VERSION ""

NS_ :

BS_:

BU_: ACC ASWS GVCU HUB_DYNO IEB IMU LOGGER

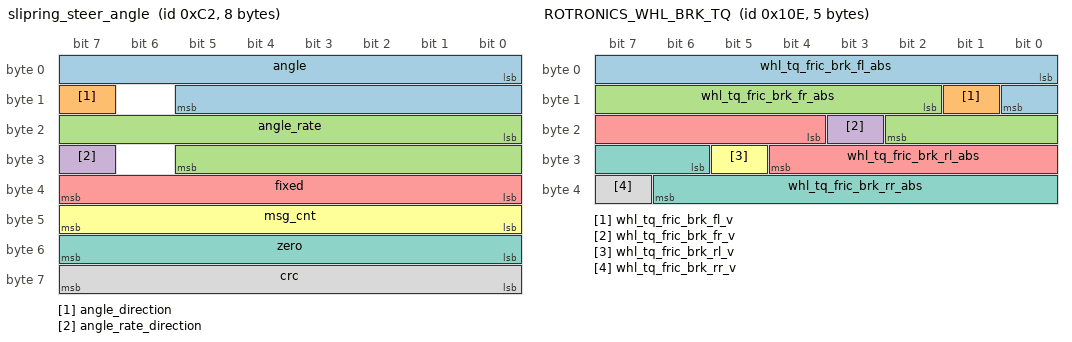
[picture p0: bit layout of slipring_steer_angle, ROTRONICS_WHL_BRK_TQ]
BO_ 194 slipring_steer_angle: 8 ASWS
 SG_ angle : 0|14@1+ (0.04372,0) [0|716] "deg"  GVCU
 SG_ angle_direction : 15|1@1+ (1,0) [0|1] "enum"  GVCU
 SG_ angle_rate : 16|14@1+ (0.04372,0) [0|716] "deg/s"  GVCU
 SG_ angle_rate_direction : 31|1@1+ (1,0) [0|1] "enum"  GVCU
 SG_ fixed : 32|8@1+ (1,0) [0|255] ""  GVCU
 SG_ msg_cnt : 40|8@1+ (1,0) [0|255] ""  GVCU
 SG_ zero : 48|8@1+ (1,0) [0|255] ""  GVCU
 SG_ crc : 56|8@1+ (1,0) [0|255] ""  GVCU

BO_ 260 ROTRONICS_SPD: 8 HUB_DYNO
 SG_ SpeedDyno1_RPM : 0|16@1+ (0.1,-2000) [-2000|4000] "rpm"  GVCU
 SG_ SpeedDyno2_RPM : 16|16@1+ (0.1,-2000) [-2000|4000] "rpm"  GVCU
 SG_ SpeedDyno3_RPM : 32|16@1+ (0.1,-2000) [-2000|4000] "rpm"  GVCU
 SG_ SpeedDyno4_RPM : 48|16@1+ (0.1,-2000) [-2000|4000] "rpm"  GVCU

BO_ 269 ROTRONICS_LIN_ACCEL: 2 HUB_DYNO
 SG_ VehicleAccelN : 0|16@1+ (0.002,-65.532) [-65.532|65.532] "m/s2"  GVCU

BO_ 270 ROTRONICS_WHL_BRK_TQ: 5 GVCU
 SG_ whl_tq_fric_brk_fl_abs : 0|9@1+ (10,0) [0|5000] "Nm"  HUB_DYNO
 SG_ whl_tq_fric_brk_fl_v : 9|1@1+ (1,0) [0|1] "bool"  HUB_DYNO
 SG_ whl_tq_fric_brk_fr_abs : 10|9@1+ (10,0) [0|5000] "Nm"  HUB_DYNO
 SG_ whl_tq_fric_brk_fr_v : 19|1@1+ (1,0) [0|1] "bool"  HUB_DYNO
 SG_ whl_tq_fric_brk_rl_abs : 20|9@1+ (10,0) [0|5000] "Nm"  HUB_DYNO
 SG_ whl_tq_fric_brk_rl_v : 29|1@1+ (1,0) [0|1] "bool"  HUB_DYNO
 SG_ whl_tq_fric_brk_rr_abs : 30|9@1+ (10,0) [0|5000] "Nm"  HUB_DYNO
 SG_ whl_tq_fric_brk_rr_v : 39|1@1+ (1,0) [0|1] "bool"  HUB_DYNO

BO_ 450 vehicle_speed_raw: 4 IEB
 SG_ e2e_checksum : 0|8@1+ (1,0) [0|255] ""  LOGGER
 SG_ e2e_alive_counter : 8|4@1+ (1,0) [0|15] "enum"  LOGGER
 SG_ vehicle_speed_r_v : 12|1@1+ (1,0) [0|1] "enum"  LOGGER
 SG_ vehicle_speed_r : 16|16@1+ (0.01,0) [0|655] "km/h"  LOGGER

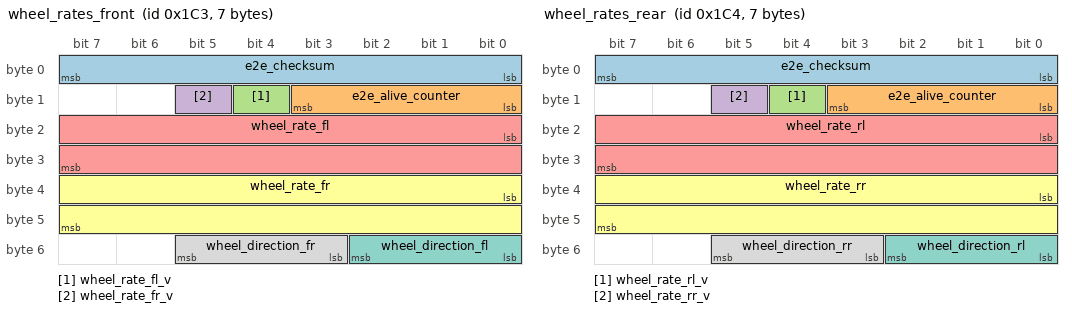
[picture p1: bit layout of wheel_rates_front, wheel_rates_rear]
BO_ 451 wheel_rates_front: 7 IEB
 SG_ e2e_checksum : 0|8@1+ (1,0) [0|255] ""  GVCU
 SG_ e2e_alive_counter : 8|4@1+ (1,0) [0|15] "enum"  GVCU
 SG_ wheel_rate_fl_v : 12|1@1+ (1,0) [0|1] "enum"  GVCU
 SG_ wheel_rate_fr_v : 13|1@1+ (1,0) [0|1] "enum"  GVCU
 SG_ wheel_rate_fl : 16|16@1+ (0.01,0) [0|655.35] "rad/s"  GVCU
 SG_ wheel_rate_fr : 32|16@1+ (0.01,0) [0|655.35] "rad/s"  GVCU
 SG_ wheel_direction_fl : 48|3@1+ (1,0) [0|5] "enum"  GVCU
 SG_ wheel_direction_fr : 51|3@1+ (1,0) [0|5] "enum"  GVCU

BO_ 452 wheel_rates_rear: 7 IEB
 SG_ e2e_checksum : 0|8@1+ (1,0) [0|255] ""  GVCU
 SG_ e2e_alive_counter : 8|4@1+ (1,0) [0|15] "enum"  GVCU
 SG_ wheel_rate_rl_v : 12|1@1+ (1,0) [0|1] "enum"  GVCU
 SG_ wheel_rate_rr_v : 13|1@1+ (1,0) [0|1] "enum"  GVCU
 SG_ wheel_rate_rl : 16|16@1+ (0.01,0) [0|655.35] "rad/s"  GVCU
 SG_ wheel_rate_rr : 32|16@1+ (0.01,0) [0|655.35] "rad/s"  GVCU
 SG_ wheel_direction_rl : 48|3@1+ (1,0) [0|5] "enum"  GVCU
 SG_ wheel_direction_rr : 51|3@1+ (1,0) [0|5] "enum"  GVCU

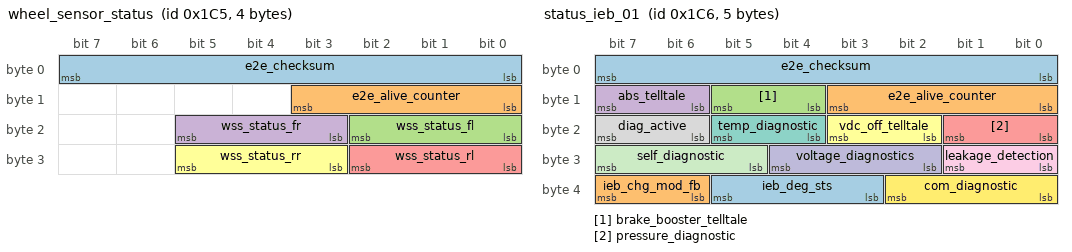
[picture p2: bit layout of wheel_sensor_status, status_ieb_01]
BO_ 453 wheel_sensor_status: 4 IEB
 SG_ e2e_checksum : 0|8@1+ (1,0) [0|255] ""  GVCU
 SG_ e2e_alive_counter : 8|4@1+ (1,0) [0|15] "enum"  GVCU
 SG_ wss_status_fl : 16|3@1+ (1,0) [0|6] "enum"  GVCU
 SG_ wss_status_fr : 19|3@1+ (1,0) [0|6] "enum"  GVCU
 SG_ wss_status_rl : 24|3@1+ (1,0) [0|6] "enum"  GVCU
 SG_ wss_status_rr : 27|3@1+ (1,0) [0|6] "enum"  GVCU

BO_ 454 status_ieb_01: 5 IEB
 SG_ e2e_checksum : 0|8@1+ (1,0) [0|255] ""  GVCU
 SG_ e2e_alive_counter : 8|4@1+ (1,0) [0|15] "enum"  GVCU
 SG_ brake_booster_telltale : 12|2@1+ (1,0) [0|2] "enum"  GVCU
 SG_ abs_telltale : 14|2@1+ (1,0) [0|2] "enum"  GVCU
 SG_ pressure_diagnostic : 16|2@1+ (1,0) [0|3] "enum"  GVCU
 SG_ vdc_off_telltale : 18|2@1+ (1,0) [0|2] "enum"  GVCU
 SG_ temp_diagnostic : 20|2@1+ (1,0) [0|3] "enum"  GVCU
 SG_ diag_active : 22|2@1+ (1,0) [0|2] "enum"  GVCU
 SG_ leakage_detection : 24|2@1+ (1,0) [0|3] "enum"  GVCU
 SG_ voltage_diagnostics : 26|3@1+ (1,0) [0|4] "enum"  GVCU
 SG_ self_diagnostic : 29|3@1+ (1,0) [0|3] "enum"  GVCU
 SG_ com_diagnostic : 32|3@1+ (1,0) [0|3] "enum"  GVCU
 SG_ ieb_deg_sts : 35|3@1+ (1,0) [0|4] "enum"  GVCU
 SG_ ieb_chg_mod_fb : 38|2@1+ (1,0) [0|2] "enum"  GVCU

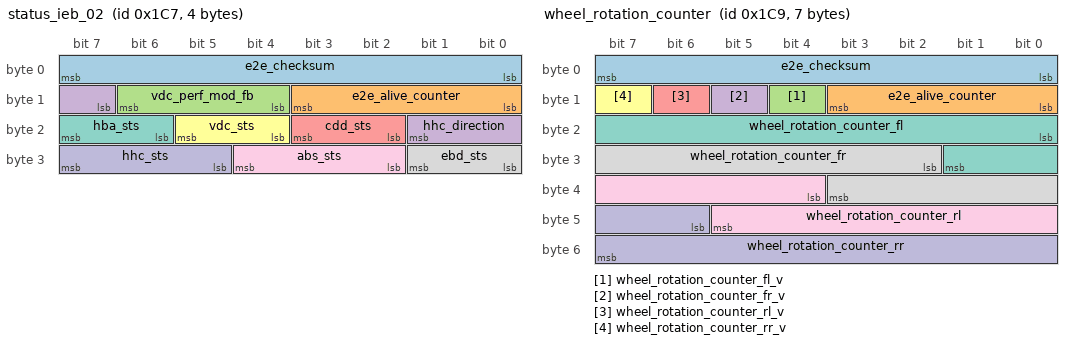
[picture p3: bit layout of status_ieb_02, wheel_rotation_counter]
BO_ 455 status_ieb_02: 4 IEB
 SG_ e2e_checksum : 0|8@1+ (1,0) [0|255] ""  GVCU
 SG_ e2e_alive_counter : 8|4@1+ (1,0) [0|15] "enum"  GVCU
 SG_ vdc_perf_mod_fb : 12|3@1+ (1,0) [0|4] "enum"  GVCU
 SG_ hhc_direction : 15|3@1+ (1,0) [0|3] "enum"  LOGGER
 SG_ cdd_sts : 18|2@1+ (1,0) [0|3] "enum"  GVCU
 SG_ vdc_sts : 20|2@1+ (1,0) [0|3] "enum"  GVCU
 SG_ hba_sts : 22|2@1+ (1,0) [0|3] "enum"  GVCU
 SG_ ebd_sts : 24|2@1+ (1,0) [0|3] "enum"  GVCU
 SG_ abs_sts : 26|3@1+ (1,0) [0|4] "enum"  GVCU
 SG_ hhc_sts : 29|3@1+ (1,0) [0|4] "enum"  GVCU

BO_ 457 wheel_rotation_counter: 7 IEB
 SG_ e2e_checksum : 0|8@1+ (1,0) [0|255] ""  GVCU
 SG_ e2e_alive_counter : 8|4@1+ (1,0) [0|15] "enum"  GVCU
 SG_ wheel_rotation_counter_fl_v : 12|1@1+ (1,0) [0|1] "enum"  GVCU
 SG_ wheel_rotation_counter_fr_v : 13|1@1+ (1,0) [0|1] "enum"  GVCU
 SG_ wheel_rotation_counter_rl_v : 14|1@1+ (1,0) [0|1] "enum"  GVCU
 SG_ wheel_rotation_counter_rr_v : 15|1@1+ (1,0) [0|1] "enum"  GVCU
 SG_ wheel_rotation_counter_fl : 16|10@1+ (1,0) [0|1023] "enum"  GVCU
 SG_ wheel_rotation_counter_fr : 26|10@1+ (1,0) [0|1023] "enum"  GVCU
 SG_ wheel_rotation_counter_rl : 36|10@1+ (1,0) [0|1023] "enum"  GVCU
 SG_ wheel_rotation_counter_rr : 46|10@1+ (1,0) [0|1023] "enum"  GVCU

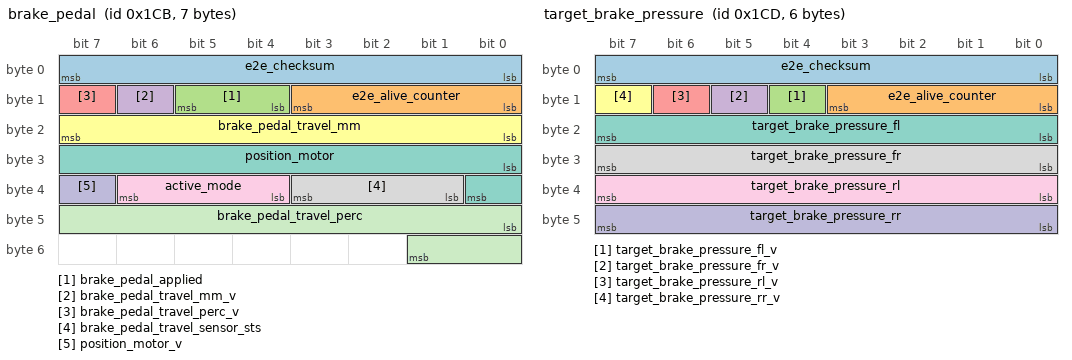
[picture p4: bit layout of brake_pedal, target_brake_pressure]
BO_ 459 brake_pedal: 7 IEB
 SG_ e2e_checksum : 0|8@1+ (1,0) [0|255] ""  GVCU
 SG_ e2e_alive_counter : 8|4@1+ (1,0) [0|15] "enum"  GVCU
 SG_ brake_pedal_applied : 12|2@1+ (1,0) [0|3] "enum"  GVCU
 SG_ brake_pedal_travel_mm_v : 14|1@1+ (1,0) [0|1] "enum"  GVCU
 SG_ brake_pedal_travel_perc_v : 15|1@1+ (1,0) [0|1] "enum"  GVCU
 SG_ brake_pedal_travel_mm : 16|8@1+ (0.1,0) [0|25.5] "mm"  GVCU
 SG_ position_motor : 24|9@1+ (0.1,-2) [-2|49.1] "mm"  GVCU
 SG_ brake_pedal_travel_sensor_sts : 33|3@1+ (1,0) [0|4] "enum"  GVCU
 SG_ active_mode : 36|3@1+ (1,0) [0|5] "enum"  GVCU
 SG_ position_motor_v : 39|1@1+ (1,0) [0|1] "enum"  GVCU
 SG_ brake_pedal_travel_perc : 40|10@1+ (0.1,0) [0|100] "%"  GVCU

BO_ 461 target_brake_pressure: 6 IEB
 SG_ e2e_checksum : 0|8@1+ (1,0) [0|255] ""  GVCU
 SG_ e2e_alive_counter : 8|4@1+ (1,0) [0|15] "enum"  GVCU
 SG_ target_brake_pressure_fl_v : 12|1@1+ (1,0) [0|1] "enum"  GVCU
 SG_ target_brake_pressure_fr_v : 13|1@1+ (1,0) [0|1] "enum"  GVCU
 SG_ target_brake_pressure_rl_v : 14|1@1+ (1,0) [0|1] "enum"  GVCU
 SG_ target_brake_pressure_rr_v : 15|1@1+ (1,0) [0|1] "enum"  GVCU
 SG_ target_brake_pressure_fl : 16|8@1+ (1,0) [0|255] "bar"  GVCU
 SG_ target_brake_pressure_fr : 24|8@1+ (1,0) [0|255] "bar"  GVCU
 SG_ target_brake_pressure_rl : 32|8@1+ (1,0) [0|255] "bar"  GVCU
 SG_ target_brake_pressure_rr : 40|8@1+ (1,0) [0|255] "bar"  GVCU

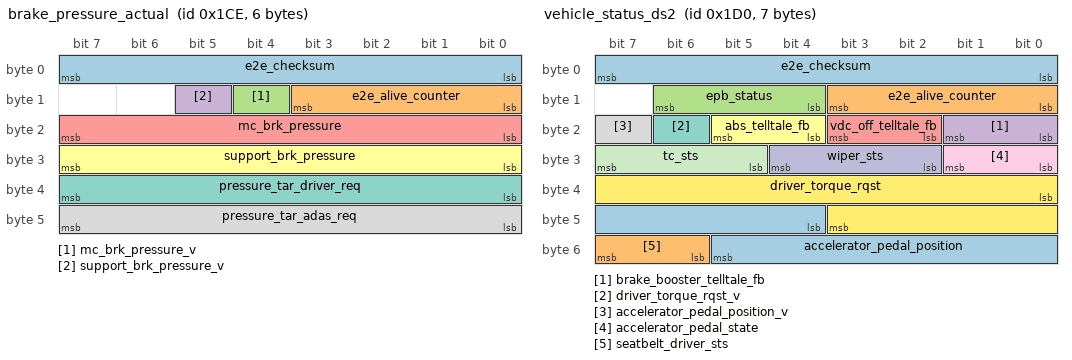
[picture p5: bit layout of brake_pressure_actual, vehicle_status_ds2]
BO_ 462 brake_pressure_actual: 6 IEB
 SG_ e2e_checksum : 0|8@1+ (1,0) [0|255] ""  GVCU
 SG_ e2e_alive_counter : 8|4@1+ (1,0) [0|15] "enum"  GVCU
 SG_ mc_brk_pressure_v : 12|1@1+ (1,0) [0|1] "enum"  GVCU
 SG_ support_brk_pressure_v : 13|1@1+ (1,0) [0|1] "enum"  GVCU
 SG_ mc_brk_pressure : 16|8@1+ (1,0) [0|255] "bar"  GVCU
 SG_ support_brk_pressure : 24|8@1+ (1,0) [0|255] "bar"  GVCU
 SG_ pressure_tar_driver_req : 32|8@1+ (1,0) [0|255] "bar"  GVCU
 SG_ pressure_tar_adas_req : 40|8@1+ (1,0) [0|255] "bar"  LOGGER

BO_ 464 vehicle_status_ds2: 7 GVCU
 SG_ e2e_checksum : 0|8@1+ (1,0) [0|255] ""  IEB
 SG_ e2e_alive_counter : 8|4@1+ (1,0) [0|15] "enum"  IEB
 SG_ epb_status : 12|3@1+ (1,0) [0|5] "enum"  IEB
 SG_ brake_booster_telltale_fb : 16|2@1+ (1,0) [0|2] "enum"  IEB
 SG_ vdc_off_telltale_fb : 18|2@1+ (1,0) [0|2] "enum"  IEB
 SG_ abs_telltale_fb : 20|2@1+ (1,0) [0|2] "enum"  IEB
 SG_ driver_torque_rqst_v : 22|1@1+ (1,0) [0|1] "enum"  IEB
 SG_ accelerator_pedal_position_v : 23|1@1+ (1,0) [0|1] "enum"  IEB
 SG_ accelerator_pedal_state : 24|2@1+ (1,0) [0|3] "enum"  IEB
 SG_ wiper_sts : 26|3@1+ (1,0) [0|4] "enum"  IEB
 SG_ tc_sts : 29|3@1+ (1,0) [0|4] "enum"  IEB
 SG_ driver_torque_rqst : 32|12@1+ (1,0) [0|4095] "Nm"  IEB
 SG_ accelerator_pedal_position : 44|10@1+ (0.1,0) [0|100] "%"  IEB
 SG_ seatbelt_driver_sts : 54|2@1+ (1,0) [0|2] "enum"  IEB

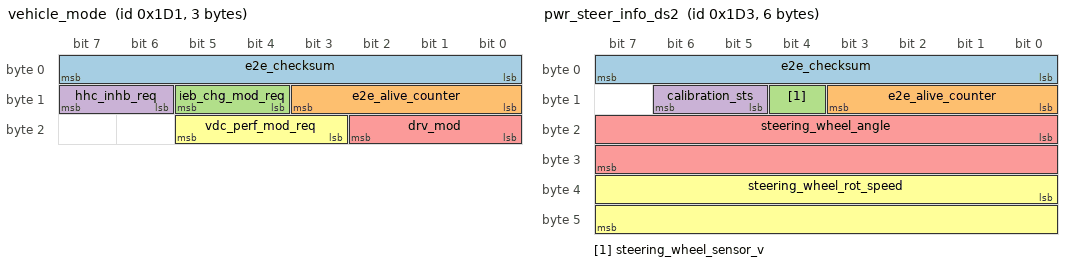
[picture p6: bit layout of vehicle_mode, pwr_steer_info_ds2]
BO_ 465 vehicle_mode: 3 GVCU
 SG_ e2e_checksum : 0|8@1+ (1,0) [0|255] ""  IEB
 SG_ e2e_alive_counter : 8|4@1+ (1,0) [0|15] "enum"  IEB
 SG_ ieb_chg_mod_req : 12|2@1+ (1,0) [0|2] "enum"  IEB
 SG_ hhc_inhb_req : 14|2@1+ (1,0) [0|2] "enum"  IEB
 SG_ drv_mod : 16|3@1+ (1,0) [0|4] "enum"  IEB
 SG_ vdc_perf_mod_req : 19|3@1+ (1,0) [0|3] "enum"  IEB

BO_ 467 pwr_steer_info_ds2: 6 GVCU
 SG_ e2e_checksum : 0|8@1+ (1,0) [0|255] ""  ACC,IEB
 SG_ e2e_alive_counter : 8|4@1+ (1,0) [0|15] "enum"  ACC,IEB
 SG_ steering_wheel_sensor_v : 12|1@1+ (1,0) [0|1] "enum"  ACC,IEB
 SG_ calibration_sts : 13|2@1+ (1,0) [0|2] "enum"  ACC,IEB
 SG_ steering_wheel_angle : 16|16@1+ (0.1,-780) [-780|780] "deg"  ACC,IEB
 SG_ steering_wheel_rot_speed : 32|16@1+ (0.1,-1016) [-1016|1016] "deg/s"  ACC,IEB

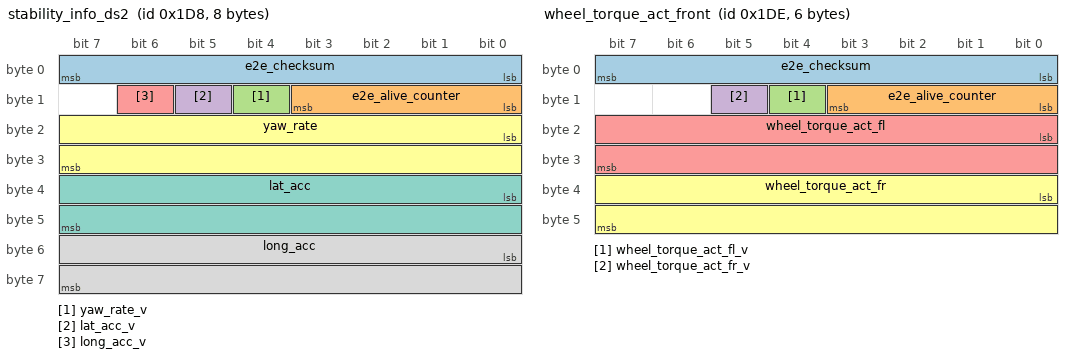
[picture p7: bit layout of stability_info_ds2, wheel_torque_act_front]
BO_ 472 stability_info_ds2: 8 GVCU
 SG_ e2e_checksum : 0|8@1+ (1,0) [0|255] ""  ACC,IEB
 SG_ e2e_alive_counter : 8|4@1+ (1,0) [0|15] "enum"  ACC,IEB
 SG_ yaw_rate_v : 12|1@1+ (1,0) [0|1] "enum"  ACC,IEB
 SG_ lat_acc_v : 13|1@1+ (1,0) [0|1] "enum"  ACC,IEB
 SG_ long_acc_v : 14|1@1+ (1,0) [0|1] "enum"  ACC,IEB
 SG_ yaw_rate : 16|16@1+ (0.005,-163.83) [-163.83|163.845] "deg/s"  ACC,IEB
 SG_ lat_acc : 32|16@1+ (0.002,-65.532) [-65.532|65.538] "m/s2"  ACC,IEB
 SG_ long_acc : 48|16@1+ (0.002,-65.532) [-65.532|65.532] "m/s2"  ACC,IEB

BO_ 475 driver_assistance_01: 2 GVCU
 SG_ e2e_checksum : 0|8@1+ (1,0) [0|255] ""  IEB
 SG_ e2e_alive_counter : 8|4@1+ (1,0) [0|15] "enum"  IEB
 SG_ brake_jerk_req : 12|2@1+ (1,0) [0|2] "enum"  IEB
 SG_ prefill_req : 14|2@1+ (1,0) [0|2] "enum"  IEB

BO_ 478 wheel_torque_act_front: 6 GVCU
 SG_ e2e_checksum : 0|8@1+ (1,0) [0|255] ""  IEB
 SG_ e2e_alive_counter : 8|4@1+ (1,0) [0|15] "enum"  IEB
 SG_ wheel_torque_act_fl_v : 12|1@1+ (1,0) [0|1] "enum"  IEB
 SG_ wheel_torque_act_fr_v : 13|1@1+ (1,0) [0|1] "enum"  IEB
 SG_ wheel_torque_act_fl : 16|16@1+ (1,-32767) [-32767|32767] "Nm"  IEB
 SG_ wheel_torque_act_fr : 32|16@1+ (1,-32767) [-32767|32767] "Nm"  IEB

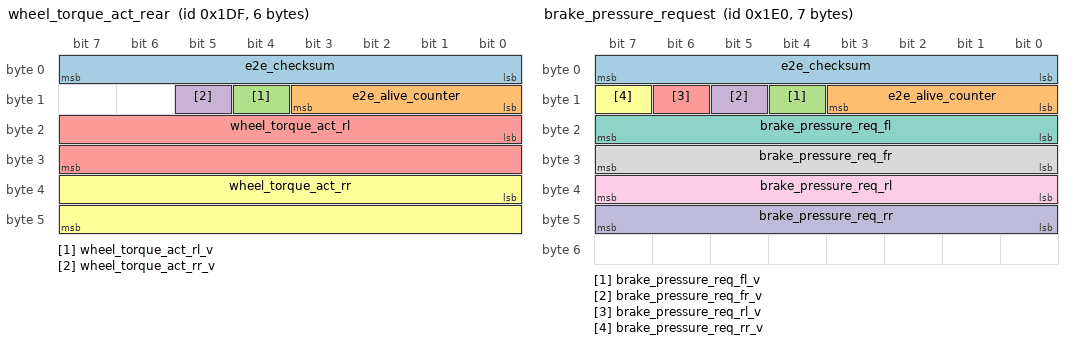
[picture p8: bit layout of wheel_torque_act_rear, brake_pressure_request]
BO_ 479 wheel_torque_act_rear: 6 GVCU
 SG_ e2e_checksum : 0|8@1+ (1,0) [0|255] ""  IEB
 SG_ e2e_alive_counter : 8|4@1+ (1,0) [0|15] "enum"  IEB
 SG_ wheel_torque_act_rl_v : 12|1@1+ (1,0) [0|1] "enum"  IEB
 SG_ wheel_torque_act_rr_v : 13|1@1+ (1,0) [0|1] "enum"  IEB
 SG_ wheel_torque_act_rl : 16|16@1+ (1,-32767) [-32767|32767] "Nm"  IEB
 SG_ wheel_torque_act_rr : 32|16@1+ (1,-32767) [-32767|32767] "Nm"  IEB

BO_ 480 brake_pressure_request: 7 GVCU
 SG_ e2e_checksum : 0|8@1+ (1,0) [0|255] ""  IEB
 SG_ e2e_alive_counter : 8|4@1+ (1,0) [0|15] "enum"  IEB
 SG_ brake_pressure_req_fl_v : 12|1@1+ (1,0) [0|1] "enum"  IEB
 SG_ brake_pressure_req_fr_v : 13|1@1+ (1,0) [0|1] "enum"  IEB
 SG_ brake_pressure_req_rl_v : 14|1@1+ (1,0) [0|1] "enum"  IEB
 SG_ brake_pressure_req_rr_v : 15|1@1+ (1,0) [0|1] "enum"  IEB
 SG_ brake_pressure_req_fl : 16|8@1+ (1,0) [0|200] "bar"  IEB
 SG_ brake_pressure_req_fr : 24|8@1+ (1,0) [0|200] "bar"  IEB
 SG_ brake_pressure_req_rl : 32|8@1+ (1,0) [0|200] "bar"  IEB
 SG_ brake_pressure_req_rr : 40|8@1+ (1,0) [0|200] "bar"  IEB

BO_ 483 regen_01: 4 IEB
 SG_ e2e_checksum : 0|8@1+ (1,0) [0|255] ""  GVCU
 SG_ e2e_alive_counter : 8|4@1+ (1,0) [0|15] "enum"  GVCU
 SG_ reg_sts : 12|2@1+ (1,0) [0|2] "enum"  GVCU
 SG_ recu_brake_torque_req_v : 14|1@1+ (1,0) [0|1] "enum"  GVCU
 SG_ recu_brake_torque_req : 16|16@1+ (1,-32767) [-32767|0] "Nm"  GVCU

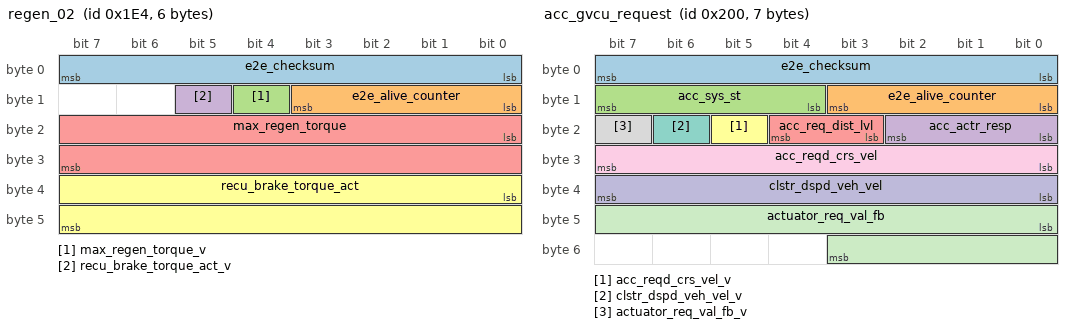
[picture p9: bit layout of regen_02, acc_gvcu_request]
BO_ 484 regen_02: 6 GVCU
 SG_ e2e_checksum : 0|8@1+ (1,0) [0|255] ""  IEB
 SG_ e2e_alive_counter : 8|4@1+ (1,0) [0|15] "enum"  IEB
 SG_ max_regen_torque_v : 12|1@1+ (1,0) [0|1] "enum"  IEB
 SG_ recu_brake_torque_act_v : 13|1@1+ (1,0) [0|1] "enum"  IEB
 SG_ max_regen_torque : 16|16@1+ (1,-32767) [-32767|0] "Nm"  IEB
 SG_ recu_brake_torque_act : 32|16@1+ (1,-32767) [-32767|0] "Nm"  IEB

BO_ 512 acc_gvcu_request: 7 GVCU
 SG_ e2e_checksum : 0|8@1+ (1,0) [0|255] ""  ACC
 SG_ e2e_alive_counter : 8|4@1+ (1,0) [0|15] "enum"  ACC
 SG_ acc_sys_st : 12|4@1+ (1,0) [0|8] "enum"  ACC
 SG_ acc_actr_resp : 16|3@1+ (1,0) [0|5] "enum"  ACC
 SG_ acc_req_dist_lvl : 19|2@1+ (1,0) [0|3] "enum"  ACC
 SG_ acc_reqd_crs_vel_v : 21|1@1+ (1,0) [0|1] "enum"  ACC
 SG_ clstr_dspd_veh_vel_v : 22|1@1+ (1,0) [0|1] "enum"  ACC
 SG_ actuator_req_val_fb_v : 23|1@1+ (1,0) [0|1] "enum"  ACC
 SG_ acc_reqd_crs_vel : 24|8@1+ (1,0) [0|255] "km/h"  ACC
 SG_ clstr_dspd_veh_vel : 32|8@1+ (1,0) [0|255] "km/h"  ACC
 SG_ actuator_req_val_fb : 40|12@1+ (0.002,-5) [-5|3.19] "m/s2"  ACC

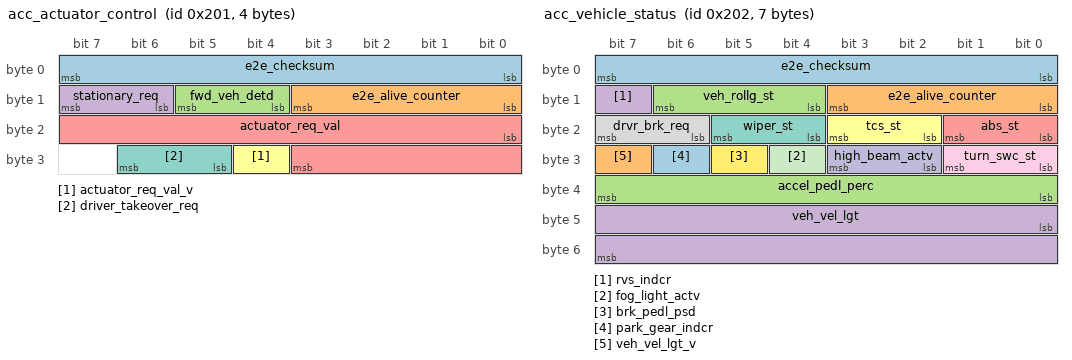
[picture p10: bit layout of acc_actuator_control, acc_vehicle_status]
BO_ 513 acc_actuator_control: 4 ACC
 SG_ e2e_checksum : 0|8@1+ (1,0) [0|255] ""  GVCU
 SG_ e2e_alive_counter : 8|4@1+ (1,0) [0|15] "enum"  GVCU
 SG_ fwd_veh_detd : 12|2@1+ (1,0) [0|2] "enum"  GVCU
 SG_ stationary_req : 14|2@1+ (1,0) [0|2] "enum"  GVCU
 SG_ actuator_req_val : 16|12@1+ (0.002,-5) [-5|3.19] "m/s2"  GVCU
 SG_ actuator_req_val_v : 28|1@1+ (1,0) [0|1] "enum"  GVCU
 SG_ driver_takeover_req : 29|2@1+ (1,0) [0|2] "enum"  GVCU

BO_ 514 acc_vehicle_status: 7 GVCU
 SG_ e2e_checksum : 0|8@1+ (1,0) [0|255] ""  ACC
 SG_ e2e_alive_counter : 8|4@1+ (1,0) [0|15] "enum"  ACC
 SG_ veh_rollg_st : 12|3@1+ (1,0) [0|4] "enum"  ACC
 SG_ rvs_indcr : 15|1@1+ (1,0) [0|1] "bool"  ACC
 SG_ abs_st : 16|2@1+ (1,0) [0|3] "enum"  ACC
 SG_ tcs_st : 18|2@1+ (1,0) [0|3] "enum"  ACC
 SG_ wiper_st : 20|2@1+ (1,0) [0|3] "enum"  ACC
 SG_ drvr_brk_req : 22|2@1+ (1,0) [0|2] "enum"  ACC
 SG_ turn_swc_st : 24|2@1+ (1,0) [0|2] "enum"  ACC
 SG_ high_beam_actv : 26|2@1+ (1,0) [0|2] "enum"  ACC
 SG_ fog_light_actv : 28|1@1+ (1,0) [0|1] "bool"  ACC
 SG_ brk_pedl_psd : 29|1@1+ (1,0) [0|1] "bool"  ACC
 SG_ park_gear_indcr : 30|1@1+ (1,0) [0|1] "bool"  ACC
 SG_ veh_vel_lgt_v : 31|1@1+ (1,0) [0|1] "enum"  ACC
 SG_ accel_pedl_perc : 32|8@1+ (0.392157,0) [0|100] "%"  ACC
 SG_ veh_vel_lgt : 40|16@1+ (0.002,0) [0|131.064] "m/s"  ACC

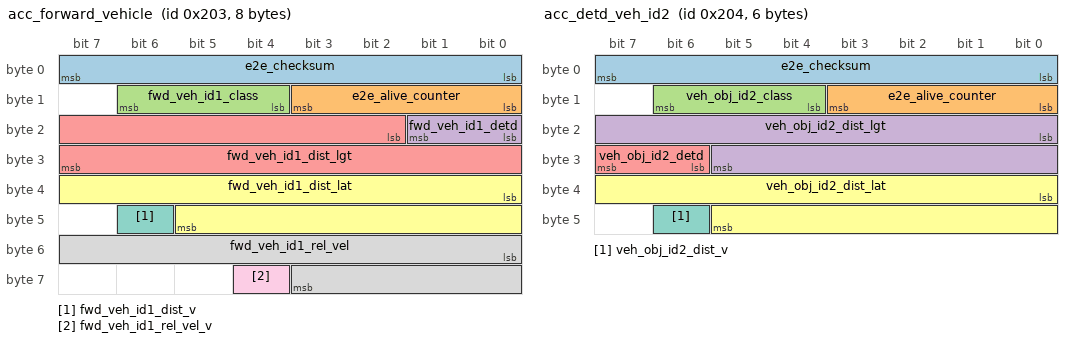
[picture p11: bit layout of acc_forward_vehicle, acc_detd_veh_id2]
BO_ 515 acc_forward_vehicle: 8 ACC
 SG_ e2e_checksum : 0|8@1+ (1,0) [0|255] ""  GVCU
 SG_ e2e_alive_counter : 8|4@1+ (1,0) [0|15] "enum"  GVCU
 SG_ fwd_veh_id1_class : 12|3@1+ (1,0) [0|4] "enum"  LOGGER
 SG_ fwd_veh_id1_detd : 16|2@1+ (1,0) [0|2] "enum"  GVCU
 SG_ fwd_veh_id1_dist_lgt : 18|14@1+ (0.02,0) [0|327.66] "m"  GVCU
 SG_ fwd_veh_id1_dist_lat : 32|14@1+ (0.02,-163.84) [-163.84|163.82] "m"  GVCU
 SG_ fwd_veh_id1_dist_v : 46|1@1+ (1,0) [0|1] "enum"  GVCU
 SG_ fwd_veh_id1_rel_vel : 48|12@1+ (0.02,-41.6) [-41.6|40.3] "m/s"  GVCU
 SG_ fwd_veh_id1_rel_vel_v : 60|1@1+ (1,0) [0|1] "enum"  GVCU

BO_ 516 acc_detd_veh_id2: 6 ACC
 SG_ e2e_checksum : 0|8@1+ (1,0) [0|255] ""  GVCU
 SG_ e2e_alive_counter : 8|4@1+ (1,0) [0|15] "enum"  GVCU
 SG_ veh_obj_id2_class : 12|3@1+ (1,0) [0|4] "enum"  GVCU
 SG_ veh_obj_id2_dist_lgt : 16|14@1+ (0.02,0) [0|327.66] "m"  GVCU
 SG_ veh_obj_id2_detd : 30|2@1+ (1,0) [0|2] "enum"  GVCU
 SG_ veh_obj_id2_dist_lat : 32|14@1+ (0.02,-163.84) [-163.84|163.82] "m"  GVCU
 SG_ veh_obj_id2_dist_v : 46|1@1+ (1,0) [0|1] "enum"  GVCU

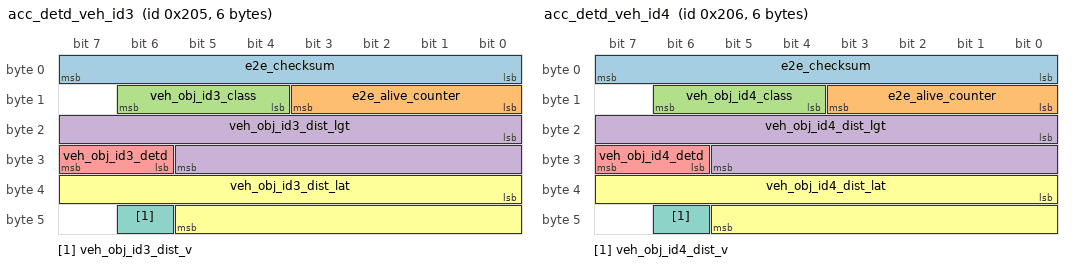
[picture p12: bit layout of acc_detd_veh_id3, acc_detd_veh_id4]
BO_ 517 acc_detd_veh_id3: 6 ACC
 SG_ e2e_checksum : 0|8@1+ (1,0) [0|255] ""  GVCU
 SG_ e2e_alive_counter : 8|4@1+ (1,0) [0|15] "enum"  GVCU
 SG_ veh_obj_id3_class : 12|3@1+ (1,0) [0|4] "enum"  GVCU
 SG_ veh_obj_id3_dist_lgt : 16|14@1+ (0.02,0) [0|327.66] "m"  GVCU
 SG_ veh_obj_id3_detd : 30|2@1+ (1,0) [0|2] "enum"  GVCU
 SG_ veh_obj_id3_dist_lat : 32|14@1+ (0.02,-163.84) [-163.84|163.82] "m"  GVCU
 SG_ veh_obj_id3_dist_v : 46|1@1+ (1,0) [0|1] "enum"  GVCU

BO_ 518 acc_detd_veh_id4: 6 ACC
 SG_ e2e_checksum : 0|8@1+ (1,0) [0|255] ""  GVCU
 SG_ e2e_alive_counter : 8|4@1+ (1,0) [0|15] "enum"  GVCU
 SG_ veh_obj_id4_class : 12|3@1+ (1,0) [0|4] "enum"  GVCU
 SG_ veh_obj_id4_dist_lgt : 16|14@1+ (0.02,0) [0|327.66] "m"  GVCU
 SG_ veh_obj_id4_detd : 30|2@1+ (1,0) [0|2] "enum"  GVCU
 SG_ veh_obj_id4_dist_lat : 32|14@1+ (0.02,-163.84) [-163.84|163.82] "m"  GVCU
 SG_ veh_obj_id4_dist_v : 46|1@1+ (1,0) [0|1] "enum"  GVCU

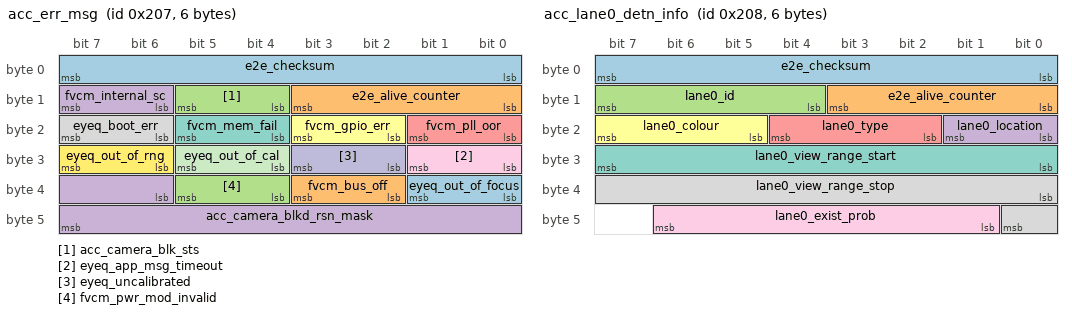
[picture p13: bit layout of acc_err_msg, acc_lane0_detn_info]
BO_ 519 acc_err_msg: 6 ACC
 SG_ e2e_checksum : 0|8@1+ (1,0) [0|255] ""  GVCU
 SG_ e2e_alive_counter : 8|4@1+ (1,0) [0|15] "enum"  GVCU
 SG_ acc_camera_blk_sts : 12|2@1+ (1,0) [0|2] "enum"  GVCU
 SG_ fvcm_internal_sc : 14|2@1+ (1,0) [0|2] "enum"  GVCU
 SG_ fvcm_pll_oor : 16|2@1+ (1,0) [0|2] "enum"  GVCU
 SG_ fvcm_gpio_err : 18|2@1+ (1,0) [0|2] "enum"  GVCU
 SG_ fvcm_mem_fail : 20|2@1+ (1,0) [0|2] "enum"  GVCU
 SG_ eyeq_boot_err : 22|2@1+ (1,0) [0|2] "enum"  GVCU
 SG_ eyeq_app_msg_timeout : 24|2@1+ (1,0) [0|2] "enum"  GVCU
 SG_ eyeq_uncalibrated : 26|2@1+ (1,0) [0|2] "enum"  GVCU
 SG_ eyeq_out_of_cal : 28|2@1+ (1,0) [0|2] "enum"  GVCU
 SG_ eyeq_out_of_rng : 30|2@1+ (1,0) [0|2] "enum"  GVCU
 SG_ eyeq_out_of_focus : 32|2@1+ (1,0) [0|2] "enum"  GVCU
 SG_ fvcm_bus_off : 34|2@1+ (1,0) [0|2] "enum"  GVCU
 SG_ fvcm_pwr_mod_invalid : 36|2@1+ (1,0) [0|2] "enum"  GVCU
 SG_ acc_camera_blkd_rsn_mask : 38|10@1+ (1,0) [0|1023] "enum"  GVCU

BO_ 520 acc_lane0_detn_info: 6 ACC
 SG_ e2e_checksum : 0|8@1+ (1,0) [0|255] ""  GVCU
 SG_ e2e_alive_counter : 8|4@1+ (1,0) [0|15] "enum"  GVCU
 SG_ lane0_id : 12|4@1+ (1,0) [0|15] "enum"  GVCU
 SG_ lane0_location : 16|2@1+ (1,0) [0|3] "enum"  GVCU
 SG_ lane0_type : 18|3@1+ (1,0) [0|6] "enum"  GVCU
 SG_ lane0_colour : 21|3@1+ (1,0) [0|4] "enum"  GVCU
 SG_ lane0_view_range_start : 24|8@1+ (0.25,0) [0|63.75] "m"  GVCU
 SG_ lane0_view_range_stop : 32|9@1+ (0.25,0) [0|127.75] "m"  GVCU
 SG_ lane0_exist_prob : 41|6@1+ (0.016,0) [0|1] "-"  GVCU

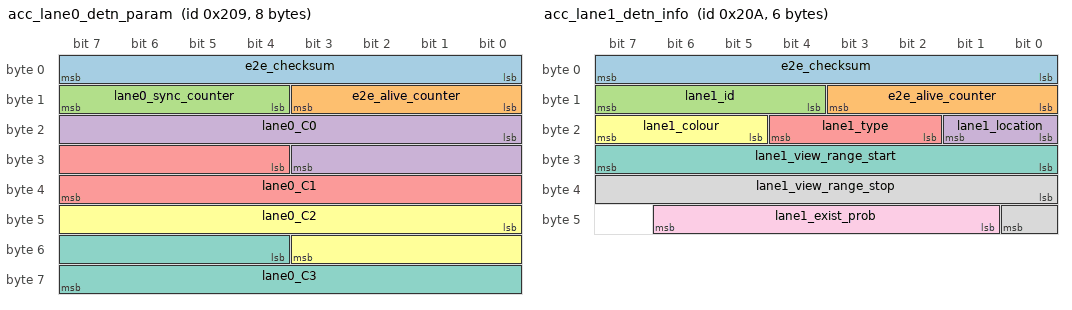
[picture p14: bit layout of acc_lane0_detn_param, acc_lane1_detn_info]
BO_ 521 acc_lane0_detn_param: 8 ACC
 SG_ e2e_checksum : 0|8@1+ (1,0) [0|255] ""  GVCU
 SG_ e2e_alive_counter : 8|4@1+ (1,0) [0|15] "enum"  GVCU
 SG_ lane0_sync_counter : 12|4@1+ (1,0) [0|15] ""  GVCU
 SG_ lane0_C0 : 16|12@1+ (0.004,-8) [-8|8] "m"  GVCU
 SG_ lane0_C1 : 28|12@1+ (0.0005,-1) [-1|1] "-"  GVCU
 SG_ lane0_C2 : 40|12@1+ (1.6e-05,-0.032) [-0.032|0.032] "m^-1"  GVCU
 SG_ lane0_C3 : 52|12@1+ (4.8e-07,-2.4e-07) [-2.4e-07|0.00196] "m^-2"  GVCU

BO_ 522 acc_lane1_detn_info: 6 ACC
 SG_ e2e_checksum : 0|8@1+ (1,0) [0|255] ""  GVCU
 SG_ e2e_alive_counter : 8|4@1+ (1,0) [0|15] "enum"  GVCU
 SG_ lane1_id : 12|4@1+ (1,0) [0|15] "enum"  GVCU
 SG_ lane1_location : 16|2@1+ (1,0) [0|3] "enum"  GVCU
 SG_ lane1_type : 18|3@1+ (1,0) [0|6] "enum"  GVCU
 SG_ lane1_colour : 21|3@1+ (1,0) [0|4] "enum"  GVCU
 SG_ lane1_view_range_start : 24|8@1+ (0.25,0) [0|63.75] "m"  GVCU
 SG_ lane1_view_range_stop : 32|9@1+ (0.25,0) [0|127.75] "m"  GVCU
 SG_ lane1_exist_prob : 41|6@1+ (0.016,0) [0|1] "-"  GVCU

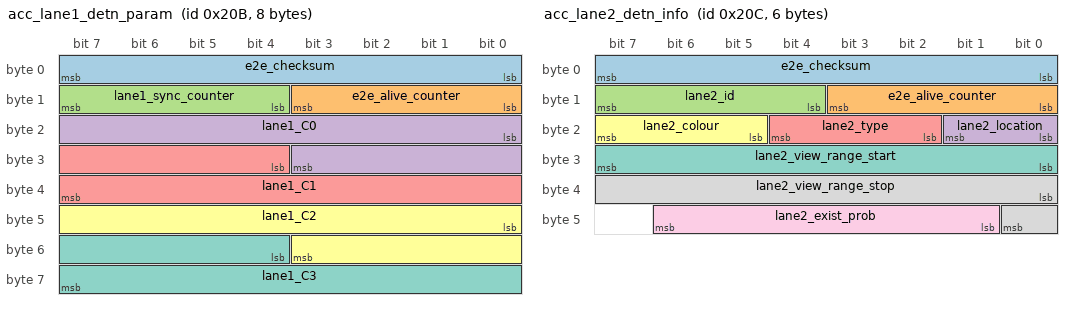
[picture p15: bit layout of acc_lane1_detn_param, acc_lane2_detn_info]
BO_ 523 acc_lane1_detn_param: 8 ACC
 SG_ e2e_checksum : 0|8@1+ (1,0) [0|255] ""  GVCU
 SG_ e2e_alive_counter : 8|4@1+ (1,0) [0|15] "enum"  GVCU
 SG_ lane1_sync_counter : 12|4@1+ (1,0) [0|15] ""  GVCU
 SG_ lane1_C0 : 16|12@1+ (0.004,-8) [-8|8] "m"  GVCU
 SG_ lane1_C1 : 28|12@1+ (0.0005,-1) [-1|1] "-"  GVCU
 SG_ lane1_C2 : 40|12@1+ (1.6e-05,-0.032) [-0.032|0.032] "m^-1"  GVCU
 SG_ lane1_C3 : 52|12@1+ (4.8e-07,-2.4e-07) [-2.4e-07|0.00196] "m^-2"  GVCU

BO_ 524 acc_lane2_detn_info: 6 ACC
 SG_ e2e_checksum : 0|8@1+ (1,0) [0|255] ""  GVCU
 SG_ e2e_alive_counter : 8|4@1+ (1,0) [0|15] "enum"  GVCU
 SG_ lane2_id : 12|4@1+ (1,0) [0|15] "enum"  GVCU
 SG_ lane2_location : 16|2@1+ (1,0) [0|3] "enum"  GVCU
 SG_ lane2_type : 18|3@1+ (1,0) [0|6] "enum"  GVCU
 SG_ lane2_colour : 21|3@1+ (1,0) [0|4] "enum"  GVCU
 SG_ lane2_view_range_start : 24|8@1+ (0.25,0) [0|63.75] "m"  GVCU
 SG_ lane2_view_range_stop : 32|9@1+ (0.25,0) [0|127.75] "m"  GVCU
 SG_ lane2_exist_prob : 41|6@1+ (0.016,0) [0|1] "-"  GVCU

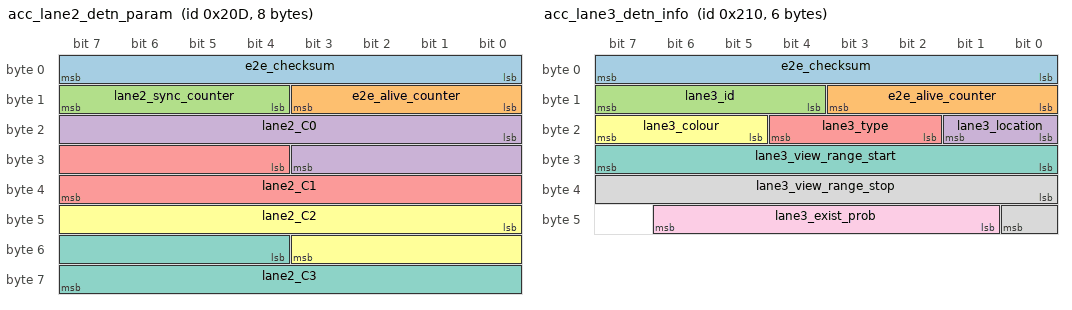
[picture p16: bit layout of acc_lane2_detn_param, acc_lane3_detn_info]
BO_ 525 acc_lane2_detn_param: 8 ACC
 SG_ e2e_checksum : 0|8@1+ (1,0) [0|255] ""  GVCU
 SG_ e2e_alive_counter : 8|4@1+ (1,0) [0|15] "enum"  GVCU
 SG_ lane2_sync_counter : 12|4@1+ (1,0) [0|15] ""  GVCU
 SG_ lane2_C0 : 16|12@1+ (0.004,-8) [-8|8] "m"  GVCU
 SG_ lane2_C1 : 28|12@1+ (0.0005,-1) [-1|1] "-"  GVCU
 SG_ lane2_C2 : 40|12@1+ (1.6e-05,-0.032) [-0.032|0.032] "m^-1"  GVCU
 SG_ lane2_C3 : 52|12@1+ (4.8e-07,-2.4e-07) [-2.4e-07|0.00196] "m^-2"  GVCU

BO_ 528 acc_lane3_detn_info: 6 ACC
 SG_ e2e_checksum : 0|8@1+ (1,0) [0|255] ""  GVCU
 SG_ e2e_alive_counter : 8|4@1+ (1,0) [0|15] "enum"  GVCU
 SG_ lane3_id : 12|4@1+ (1,0) [0|15] "enum"  GVCU
 SG_ lane3_location : 16|2@1+ (1,0) [0|3] "enum"  GVCU
 SG_ lane3_type : 18|3@1+ (1,0) [0|6] "enum"  GVCU
 SG_ lane3_colour : 21|3@1+ (1,0) [0|4] "enum"  GVCU
 SG_ lane3_view_range_start : 24|8@1+ (0.25,0) [0|63.75] "m"  GVCU
 SG_ lane3_view_range_stop : 32|9@1+ (0.25,0) [0|127.75] "m"  GVCU
 SG_ lane3_exist_prob : 41|6@1+ (0.016,0) [0|1] "-"  GVCU

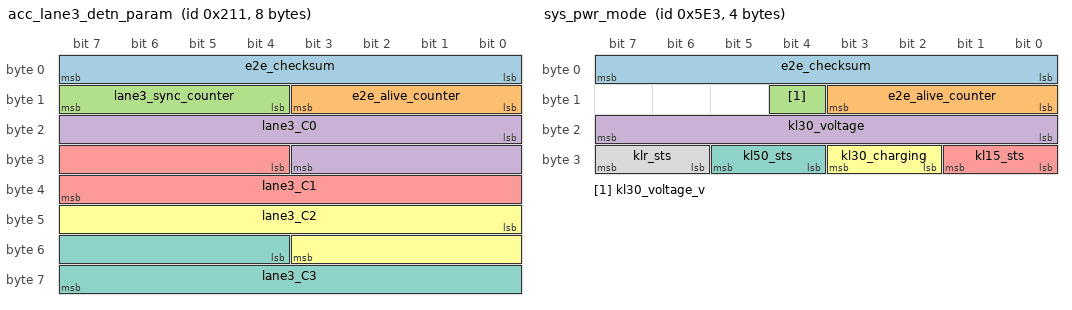
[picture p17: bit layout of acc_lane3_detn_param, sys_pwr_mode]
BO_ 529 acc_lane3_detn_param: 8 ACC
 SG_ e2e_checksum : 0|8@1+ (1,0) [0|255] ""  GVCU
 SG_ e2e_alive_counter : 8|4@1+ (1,0) [0|15] "enum"  GVCU
 SG_ lane3_sync_counter : 12|4@1+ (1,0) [0|15] ""  GVCU
 SG_ lane3_C0 : 16|12@1+ (0.004,-8) [-8|8] "m"  GVCU
 SG_ lane3_C1 : 28|12@1+ (0.0005,-1) [-1|1] "-"  GVCU
 SG_ lane3_C2 : 40|12@1+ (1.6e-05,-0.032) [-0.032|0.032] "m^-1"  GVCU
 SG_ lane3_C3 : 52|12@1+ (4.8e-07,-2.4e-07) [-2.4e-07|0.00196] "m^-2"  GVCU

BO_ 1470 sec_stat_ieb: 7 IEB
 SG_ e2e_checksum : 0|8@1+ (1,0) [0|255] ""  GVCU
 SG_ e2e_alive_counter : 8|4@1+ (1,0) [0|15] "enum"  GVCU
 SG_ e2e_crc_err_cnt : 16|16@1+ (1,0) [0|65535] "enum"  GVCU
 SG_ e2e_alive_cnt_err_cnt : 32|16@1+ (1,0) [0|65535] "enum"  GVCU
 SG_ sa_fail_attempt_cnt : 48|8@1+ (1,0) [0|255] "enum"  GVCU

BO_ 1471 sec_stat_acc: 7 ACC
 SG_ e2e_checksum : 0|8@1+ (1,0) [0|255] ""  GVCU
 SG_ e2e_alive_counter : 8|4@1+ (1,0) [0|15] "enum"  GVCU
 SG_ e2e_crc_err_cnt : 16|16@1+ (1,0) [0|65535] "enum"  GVCU
 SG_ e2e_alive_cnt_err_cnt : 32|16@1+ (1,0) [0|65535] "enum"  GVCU
 SG_ sa_fail_attempt_cnt : 48|8@1+ (1,0) [0|255] "enum"  GVCU

BO_ 1500 odometer_value: 6 GVCU
 SG_ e2e_checksum : 0|8@1+ (1,0) [0|255] ""  ACC,IEB
 SG_ e2e_alive_counter : 8|4@1+ (1,0) [0|15] "enum"  ACC,IEB
 SG_ veh_odo_v : 12|1@1+ (1,0) [0|1] "enum"  ACC,IEB
 SG_ veh_odo : 16|32@1+ (0.015625,0) [0|67108863.984] "km"  ACC,IEB

BO_ 1507 sys_pwr_mode: 4 GVCU
 SG_ e2e_checksum : 0|8@1+ (1,0) [0|255] ""  ACC
 SG_ e2e_alive_counter : 8|4@1+ (1,0) [0|15] "enum"  ACC
 SG_ kl30_voltage_v : 12|1@1+ (1,0) [0|1] "enum"  ACC
 SG_ kl30_voltage : 16|8@1+ (0.1,0) [0|25.5] "V"  ACC
 SG_ kl15_sts : 24|2@1+ (1,0) [0|3] "enum"  ACC
 SG_ kl30_charging : 26|2@1+ (1,0) [0|2] "enum"  ACC
 SG_ kl50_sts : 28|2@1+ (1,0) [0|2] "enum"  ACC
 SG_ klr_sts : 30|2@1+ (1,0) [0|2] "enum"  ACC

BO_ 1510 nm_request_gvcu_ds2: 2 GVCU
 SG_ e2e_checksum : 0|8@1+ (1,0) [0|255] ""  ACC,IEB
 SG_ e2e_alive_counter : 8|4@1+ (1,0) [0|15] "enum"  ACC,IEB
 SG_ nm_request : 12|4@1+ (1,0) [0|4] "enum"  ACC,IEB

BO_ 1513 nm_status_ieb: 2 IEB
 SG_ e2e_checksum : 0|8@1+ (1,0) [0|255] ""  GVCU
 SG_ e2e_alive_counter : 8|4@1+ (1,0) [0|15] "enum"  GVCU
 SG_ nm_status : 12|4@1+ (1,0) [0|12] "enum"  GVCU

BO_ 1515 nm_status_acc: 2 ACC
 SG_ e2e_checksum : 0|8@1+ (1,0) [0|255] ""  GVCU
 SG_ e2e_alive_counter : 8|4@1+ (1,0) [0|15] "enum"  GVCU
 SG_ nm_status : 12|4@1+ (1,0) [0|12] "enum"  GVCU

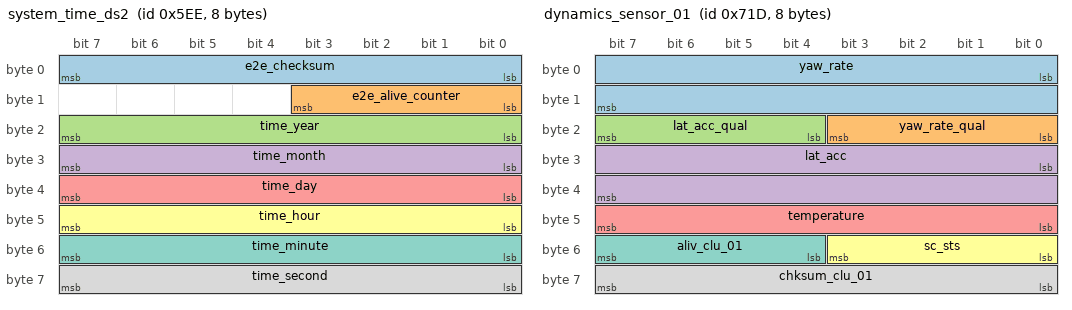
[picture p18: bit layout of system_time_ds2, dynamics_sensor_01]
BO_ 1518 system_time_ds2: 8 GVCU
 SG_ e2e_checksum : 0|8@1+ (1,0) [0|255] ""  ACC,IEB
 SG_ e2e_alive_counter : 8|4@1+ (1,0) [0|15] "enum"  ACC,IEB
 SG_ time_year : 16|8@1+ (1,2010) [2010|2265] "years"  ACC,IEB
 SG_ time_month : 24|8@1+ (1,0) [1|12] "mon"  ACC,IEB
 SG_ time_day : 32|8@1+ (1,0) [1|31] "d"  ACC,IEB
 SG_ time_hour : 40|8@1+ (1,0) [0|23] "h"  ACC,IEB
 SG_ time_minute : 48|8@1+ (1,0) [0|59] "min"  ACC,IEB
 SG_ time_second : 56|8@1+ (1,0) [0|59] "s"  ACC,IEB

BO_ 1614 xcp_cmd_ieb: 8 GVCU
 SG_ command : 0|64@1+ (1,0) [0|0] ""  IEB

BO_ 1615 xcp_resp_ieb: 8 IEB
 SG_ response : 0|64@1+ (1,0) [0|0] ""  GVCU

BO_ 1821 dynamics_sensor_01: 8 IMU
 SG_ yaw_rate : 0|16@1+ (0.005,-163.83) [-163.83|163.845] "deg/s"  GVCU
 SG_ yaw_rate_qual : 16|4@1+ (1,0) [0|15] "enum"  GVCU
 SG_ lat_acc_qual : 20|4@1+ (1,0) [0|15] "enum"  GVCU
 SG_ lat_acc : 24|16@1+ (0.002,-65.532) [-65.532|65.538] "m/s2"  GVCU
 SG_ temperature : 40|8@1+ (1,-50) [-50|205] "deg C"  GVCU
 SG_ sc_sts : 48|4@1+ (1,0) [0|15] "enum"  GVCU
 SG_ aliv_clu_01 : 52|4@1+ (1,0) [0|15] ""  GVCU
 SG_ chksum_clu_01 : 56|8@1+ (1,0) [0|255] ""  GVCU

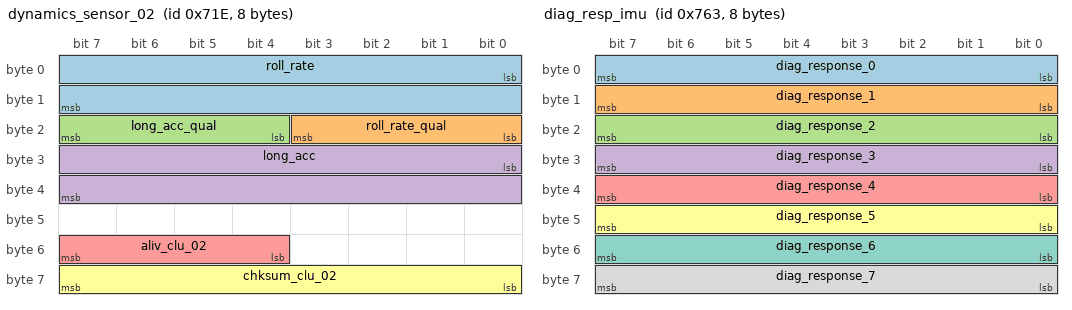
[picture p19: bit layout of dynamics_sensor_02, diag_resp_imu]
BO_ 1822 dynamics_sensor_02: 8 IMU
 SG_ roll_rate : 0|16@1+ (0.005,-163.83) [-163.83|163.845] "deg/s"  GVCU
 SG_ roll_rate_qual : 16|4@1+ (1,0) [0|15] "enum"  GVCU
 SG_ long_acc_qual : 20|4@1+ (1,0) [0|15] "enum"  GVCU
 SG_ long_acc : 24|16@1+ (0.002,-65.532) [-65.532|65.538] "m/s2"  GVCU
 SG_ aliv_clu_02 : 52|4@1+ (1,0) [0|15] ""  GVCU
 SG_ chksum_clu_02 : 56|8@1+ (1,0) [0|255] ""  GVCU

BO_ 1823 dynamics_sensor_03: 8 IMU
 SG_ pitch_rate : 0|16@1+ (0.005,-163.83) [-163.83|163.845] "deg/s"  GVCU
 SG_ pitch_rate_qual : 16|4@1+ (1,0) [0|15] "enum"  GVCU
 SG_ vert_acc_qual : 20|4@1+ (1,0) [0|15] "enum"  GVCU
 SG_ vert_acc : 24|16@1+ (0.002,-65.532) [-65.532|65.538] "m/s2"  GVCU
 SG_ aliv_clu_03 : 52|4@1+ (1,0) [0|15] ""  GVCU
 SG_ chksum_clu_03 : 56|8@1+ (1,0) [0|255] ""  GVCU

BO_ 1831 dynamics_sensor_ident_01: 8 IMU
 SG_ identification_number_0 : 0|8@1+ (1,0) [0|255] ""  GVCU
 SG_ identification_number_1 : 8|8@1+ (1,0) [0|255] ""  GVCU
 SG_ identification_number_2 : 16|8@1+ (1,0) [0|255] ""  GVCU
 SG_ identification_number_3 : 24|8@1+ (1,0) [0|255] ""  GVCU
 SG_ identification_number_4 : 32|8@1+ (1,0) [0|255] ""  GVCU

BO_ 1832 dynamics_sensor_ident_02: 8 IMU
 SG_ identification_number_5 : 0|8@1+ (1,0) [0|255] ""  GVCU
 SG_ identification_number_6 : 8|8@1+ (1,0) [0|255] ""  GVCU
 SG_ identification_number_7 : 16|8@1+ (1,0) [0|255] ""  GVCU
 SG_ identification_number_8 : 24|8@1+ (1,0) [0|255] ""  GVCU
 SG_ identification_number_9 : 32|8@1+ (1,0) [0|255] ""  GVCU

BO_ 1890 diag_req_imu_g2: 4 GVCU
 SG_ diag_request : 0|4@1+ (1,0) [0|15] "enum"  IMU
 SG_ reset_request : 4|4@1+ (1,0) [0|15] "enum"  IMU

BO_ 1891 diag_resp_imu: 8 IMU
 SG_ diag_response_0 : 0|8@1+ (1,0) [0|0] ""  GVCU
 SG_ diag_response_1 : 8|8@1+ (1,0) [0|0] ""  GVCU
 SG_ diag_response_2 : 16|8@1+ (1,0) [0|0] ""  GVCU
 SG_ diag_response_3 : 24|8@1+ (1,0) [0|0] ""  GVCU
 SG_ diag_response_4 : 32|8@1+ (1,0) [0|0] ""  GVCU
 SG_ diag_response_5 : 40|8@1+ (1,0) [0|0] ""  GVCU
 SG_ diag_response_6 : 48|8@1+ (1,0) [0|0] ""  GVCU
 SG_ diag_response_7 : 56|8@1+ (1,0) [0|0] ""  GVCU

BO_ 1989 diag_req_ieb_g2: 8 GVCU
 SG_ diag_data : 0|64@1+ (1,0) [0|0] ""  IEB

BO_ 1995 diag_acc_phys_req_fvcm_g2: 8 GVCU
 SG_ DiagnosticPhysAddrReq : 0|64@1+ (1,0) [0|0] ""  ACC

BO_ 1997 diag_resp_ieb: 8 IEB
 SG_ diag_data : 0|64@1+ (1,0) [0|0] ""  GVCU

BO_ 2002 diag_acc_phys_resp_fvcm: 8 ACC
 SG_ DiagnosticPhysResp_FVCM : 0|64@1+ (1,0) [0|0] ""  GVCU

BO_ 2003 diag_acc_dtc_info_fvcm: 6 ACC
 SG_ dtc_severity_level : 0|4@1+ (1,0) [0|15] "enum"  GVCU
 SG_ dtc_high_byte : 8|8@1+ (1,0) [0|255] "enum"  GVCU
 SG_ dtc_low_byte : 16|8@1+ (1,0) [0|255] "enum"  GVCU
 SG_ dtc_failure_type_byte : 24|8@1+ (1,0) [0|255] "enum"  GVCU
 SG_ dtc_status : 32|8@1+ (1,0) [0|255] "enum"  GVCU
 SG_ dtc_type : 40|8@1+ (1,0) [0|255] "enum"  GVCU

BO_ 2006 diag_ds2_func_req_g2: 8 GVCU
 SG_ DiagnosticFuncAddrReq : 0|64@1+ (1,0) [0|0] ""  ACC,IEB

CM_ BU_ ACC "ADAS ECU";
CM_ BU_ GVCU "Vehicle Control Module";
CM_ BU_ HUB_DYNO "HUB DYNO";
CM_ BU_ IEB "Intelligent Electronic Brake System";
CM_ BU_ IMU "Inertial Measurement Unit";
CM_ BO_ 194 "Jesko slip ring";
CM_ SG_ 194 angle "Filtered";
CM_ SG_ 194 angle_direction "Filtered";
CM_ BO_ 260 "OBS: Message rate should be 5 ms but the dyno is sending at 10 ms";
CM_ BO_ 270 "For hub dyno usage only";
CM_ BO_ 450 "Vehicle speed at CoG";
CM_ SG_ 450 e2e_checksum "CRC check value according to specification E2E";
CM_ SG_ 450 e2e_alive_counter "Alive counter for E2E";
CM_ SG_ 450 vehicle_speed_r_v "Valid signal";
CM_ SG_ 450 vehicle_speed_r "Vehicle speed at CoG";
CM_ BO_ 451 "Front WSS Speed";
CM_ SG_ 451 e2e_checksum "CRC check value according to specification E2E";
CM_ SG_ 451 e2e_alive_counter "Alive counter for E2E";
CM_ SG_ 451 wheel_rate_fl_v "Valid signal";
CM_ SG_ 451 wheel_rate_fr_v "Valid signal";
CM_ SG_ 451 wheel_rate_fl "wheel rate front left";
CM_ SG_ 451 wheel_rate_fr "wheel rate front right";
CM_ SG_ 451 wheel_direction_fl "Direction FL wheel";
CM_ SG_ 451 wheel_direction_fr "Direction FR wheel";
CM_ BO_ 452 "Rear WSS Speed";
CM_ SG_ 452 e2e_checksum "CRC check value according to specification E2E";
CM_ SG_ 452 e2e_alive_counter "Alive counter for E2E";
CM_ SG_ 452 wheel_rate_rl_v "Valid signal";
CM_ SG_ 452 wheel_rate_rr_v "Valid signal";
CM_ SG_ 452 wheel_rate_rl "wheel rate rear left";
CM_ SG_ 452 wheel_rate_rr "wheel rate rear right";
CM_ SG_ 452 wheel_direction_rl "Direction RL wheel";
CM_ SG_ 452 wheel_direction_rr "Direction RR wheel";
CM_ BO_ 453 "Report of wheel speed sensor faults";
CM_ SG_ 453 e2e_checksum "CRC check value according to specification E2E";
CM_ SG_ 453 e2e_alive_counter "Alive counter for E2E";
CM_ SG_ 453 wss_status_fl "Front Left Wheel Speed Sensor Diag";
CM_ SG_ 453 wss_status_fr "Front Right Wheel Speed Sensor Diag";
CM_ SG_ 453 wss_status_rl "Rear Left Wheel Speed Sensor Diag";
CM_ SG_ 453 wss_status_rr "Rear Right Wheel Speed Sensor Diag";
CM_ BO_ 454 "status values IEB";
CM_ SG_ 454 e2e_checksum "CRC check value according to specification E2E";
CM_ SG_ 454 e2e_alive_counter "Alive counter for E2E";
CM_ SG_ 454 brake_booster_telltale "Genera brake booster failure information for cluster";
CM_ SG_ 454 abs_telltale "ABS telltale information for cluster";
CM_ SG_ 454 pressure_diagnostic "pressure diagnostic";
CM_ SG_ 454 vdc_off_telltale "VDC off telltale information for cluster";
CM_ SG_ 454 temp_diagnostic "diagnostic temperature";
CM_ SG_ 454 diag_active "IEB diagnostic active";
CM_ SG_ 454 leakage_detection "IEB has detected a leakage in it's hydraulics";
CM_ SG_ 454 voltage_diagnostics "diagnosis supply voltage";
CM_ SG_ 454 self_diagnostic "Communication checks
Failed to build pressure
Voltage checks
Temperature checks eBooster fail-request HBC";
CM_ SG_ 454 com_diagnostic "- message timeouts
- invalid values / values out of range
- wrong e2e received";
CM_ SG_ 454 ieb_deg_sts "working status of IEB

DEGRADE_1 -> ~ 100 bar max pressure
DEGRADE_2 -> ~ 70 bar max pressure
DEGRADE_3 -> ~ hydraulic backup";
CM_ SG_ 454 ieb_chg_mod_fb "Feedback if IEB modes changes are allowed or not";
CM_ BO_ 455 "status values IEB";
CM_ SG_ 455 e2e_checksum "CRC check value according to specification E2E";
CM_ SG_ 455 e2e_alive_counter "Alive counter for E2E";
CM_ SG_ 455 vdc_perf_mod_fb "IEB responds to GVCU and SmartCenter with the current VDC Level status";
CM_ SG_ 455 hhc_direction "Hill hold control direction of vehicle, uphill or downhill";
CM_ SG_ 455 cdd_sts "Auto brake status";
CM_ SG_ 455 vdc_sts "Status of VDC
VDC active - capable of intervening
off - deactivated by driver
intervening - actuating
failure - fail state
VDC status valid signal";
CM_ SG_ 455 hba_sts "Hydraulic Brake Assist Active";
CM_ SG_ 455 ebd_sts "Electrical Brake Distribution Active";
CM_ SG_ 455 abs_sts "ABS status
ABS active - capable of intervening
off - deactivated by driver
intervening - actuating
failure - fail state
";
CM_ SG_ 455 hhc_sts "Hill Hold Control Active";
CM_ BO_ 457 "Rotational counter for WSS";
CM_ SG_ 457 e2e_checksum "CRC check value according to specification E2E";
CM_ SG_ 457 e2e_alive_counter "Alive counter for E2E";
CM_ SG_ 457 wheel_rotation_counter_fl_v "Valid signal";
CM_ SG_ 457 wheel_rotation_counter_fr_v "Valid signal";
CM_ SG_ 457 wheel_rotation_counter_rl_v "Valid signal";
CM_ SG_ 457 wheel_rotation_counter_rr_v "Valid signal";
CM_ SG_ 457 wheel_rotation_counter_fl "Wheel rotation counts";
CM_ SG_ 457 wheel_rotation_counter_fr "Wheel rotation counts";
CM_ SG_ 457 wheel_rotation_counter_rl "Wheel rotation counts";
CM_ SG_ 457 wheel_rotation_counter_rr "Wheel rotation counts";
CM_ BO_ 459 "brake pedal values";
CM_ SG_ 459 e2e_checksum "CRC check value according to specification E2E";
CM_ SG_ 459 e2e_alive_counter "Alive counter for E2E";
CM_ SG_ 459 brake_pedal_applied "Brake pedal applied";
CM_ SG_ 459 brake_pedal_travel_mm_v "brake pedal position in mm valid signal";
CM_ SG_ 459 brake_pedal_travel_perc_v "brake pedal position in percentage valid signal";
CM_ SG_ 459 brake_pedal_travel_mm "brake pedal position in mm";
CM_ SG_ 459 position_motor "position of support motor in mm";
CM_ SG_ 459 brake_pedal_travel_sensor_sts "brake pedal sensor status";
CM_ SG_ 459 active_mode "current brake mode";
CM_ SG_ 459 position_motor_v "position of motor valid signal";
CM_ SG_ 459 brake_pedal_travel_perc "brake pedal position in percentage";
CM_ BO_ 461 "target brake pressures per wheel";
CM_ SG_ 461 e2e_checksum "CRC check value according to specification E2E";
CM_ SG_ 461 e2e_alive_counter "Alive counter for E2E";
CM_ SG_ 461 target_brake_pressure_fl_v "target pressure for front left brake valid signal";
CM_ SG_ 461 target_brake_pressure_fr_v "target pressure for front right brake valid signal";
CM_ SG_ 461 target_brake_pressure_rl_v "target pressure for rear left brake valid signal";
CM_ SG_ 461 target_brake_pressure_rr_v "target pressure for rear right brake valid signal";
CM_ SG_ 461 target_brake_pressure_fl "target pressure for front left brake";
CM_ SG_ 461 target_brake_pressure_fr "target pressure for front right brake";
CM_ SG_ 461 target_brake_pressure_rl "target pressure for rear left brake";
CM_ SG_ 461 target_brake_pressure_rr "target pressure for rear right brake";
CM_ BO_ 462 "output pressure master cylinder";
CM_ SG_ 462 e2e_checksum "CRC check value according to specification E2E";
CM_ SG_ 462 e2e_alive_counter "Alive counter for E2E";
CM_ SG_ 462 mc_brk_pressure_v "Valid signal, 1 = Valid";
CM_ SG_ 462 support_brk_pressure_v "Valid signal, 1 = Valid";
CM_ SG_ 462 mc_brk_pressure "master cylinder brake pressure";
CM_ SG_ 462 support_brk_pressure "output pressure generated by the brake booster";
CM_ SG_ 462 pressure_tar_driver_req "target pressure based on driver's pedal input";
CM_ SG_ 462 pressure_tar_adas_req "target pressure based on adas request";
CM_ BO_ 464 "vehicle status";
CM_ SG_ 464 e2e_checksum "CRC check value according to specification E2E";
CM_ SG_ 464 e2e_alive_counter "Alive counter for E2E";
CM_ SG_ 464 epb_status "Electric parking brake status";
CM_ SG_ 464 brake_booster_telltale_fb "Feedback of brake telltale in cluster";
CM_ SG_ 464 vdc_off_telltale_fb "Feedback of VDC off telltalte in cluster";
CM_ SG_ 464 abs_telltale_fb "Feedback of ans telltale in cluster";
CM_ SG_ 464 driver_torque_rqst_v "Driver torque request (possible used for hill hold function release by IEB) valid signal";
CM_ SG_ 464 accelerator_pedal_position_v "Acceleration pedal position in % valid";
CM_ SG_ 464 accelerator_pedal_state "Status of accelerator pedal";
CM_ SG_ 464 wiper_sts "signal to indicate if the wiper is engaged or not";
CM_ SG_ 464 tc_sts "Traction control status
TC active - capable of intervening
off - deactivated by driver
intervening - actuating
failure - fail state";
CM_ SG_ 464 driver_torque_rqst "Driver torque request (possible used for hill hold function release by IEB) as an absolut value";
CM_ SG_ 464 accelerator_pedal_position "Accelerator pedal position in %";
CM_ SG_ 464 seatbelt_driver_sts "information about driver's seat belt";
CM_ BO_ 465 "set Vehicle Dynamics Levels";
CM_ SG_ 465 e2e_checksum "CRC check value according to specification E2E";
CM_ SG_ 465 e2e_alive_counter "Alive counter for E2E";
CM_ SG_ 465 ieb_chg_mod_req "Allow changing in IEB modes (i.e. VDC perf mod), if DISABLED then IEB must NOT listen to related signals (i.e. VDC should be kept ON even if vdc_perf_mod_req says OFF)";
CM_ SG_ 465 hhc_inhb_req "Control signal to request HHC function to be inhibited or allowed";
CM_ SG_ 465 drv_mod "set vehicle's drive mode";
CM_ SG_ 465 vdc_perf_mod_req "VDC status request to IEB";
CM_ BO_ 467 "basic steering values";
CM_ SG_ 467 e2e_checksum "CRC check value according to specification E2E";
CM_ SG_ 467 e2e_alive_counter "Alive counter for E2E";
CM_ SG_ 467 steering_wheel_sensor_v "valid signal for steering wheel angle and steering whel rotation speed as the source for these two signals is the same sensor. It's not possible that one singal is valid and the other is not";
CM_ SG_ 467 calibration_sts "steering angle sensor calibration status";
CM_ SG_ 467 steering_wheel_angle "steering wheel angle";
CM_ SG_ 467 steering_wheel_rot_speed "steering wheel rotation speed";
CM_ BO_ 472 "Gyro(CoG): YawRate";
CM_ SG_ 472 e2e_checksum "CRC check value according to specification E2E";
CM_ SG_ 472 e2e_alive_counter "Alive counter for E2E";
CM_ SG_ 472 yaw_rate_v "yaw rate valid signal";
CM_ SG_ 472 lat_acc_v "lateral acceleration valid signal";
CM_ SG_ 472 long_acc_v "longitudinal accleration valid signal";
CM_ SG_ 472 yaw_rate "yaw rate";
CM_ SG_ 472 lat_acc "Lateral acceleration (Y-axis)";
CM_ SG_ 472 long_acc "Longitudal acceleration (X-axis)";
CM_ BO_ 475 "Advanced driving";
CM_ SG_ 475 e2e_checksum "CRC check value according to specification E2E";
CM_ SG_ 475 e2e_alive_counter "Alive counter for E2E";
CM_ SG_ 475 brake_jerk_req "ADAS AEB brake jerk request status";
CM_ SG_ 475 prefill_req "ADAS brake prefill request status";
CM_ BO_ 478 "Wheel torque front wheels";
CM_ SG_ 478 e2e_checksum "CRC check value according to specification E2E";
CM_ SG_ 478 e2e_alive_counter "Alive counter for E2E";
CM_ SG_ 478 wheel_torque_act_fl_v "Valid signal";
CM_ SG_ 478 wheel_torque_act_fr_v "Valid signal";
CM_ SG_ 478 wheel_torque_act_fl "torque from drivetrain fl";
CM_ SG_ 478 wheel_torque_act_fr "torque from drivetrain fr";
CM_ BO_ 479 "Wheel torque rear wheels";
CM_ SG_ 479 e2e_checksum "CRC check value according to specification E2E";
CM_ SG_ 479 e2e_alive_counter "Alive counter for E2E";
CM_ SG_ 479 wheel_torque_act_rl_v "Valid signal";
CM_ SG_ 479 wheel_torque_act_rr_v "Valid signal";
CM_ SG_ 479 wheel_torque_act_rl "torque from drivetrain rl";
CM_ SG_ 479 wheel_torque_act_rr "torque from drivetrain rr";
CM_ BO_ 480 "Requested brake pressure from GVCU to IEB";
CM_ SG_ 480 e2e_checksum "CRC check value according to specification E2E";
CM_ SG_ 480 e2e_alive_counter "Alive counter for E2E";
CM_ SG_ 480 brake_pressure_req_fl_v "Valid signal";
CM_ SG_ 480 brake_pressure_req_fr_v "Valid signal";
CM_ SG_ 480 brake_pressure_req_rl_v "Valid signal";
CM_ SG_ 480 brake_pressure_req_rr_v "Valid signal";
CM_ SG_ 480 brake_pressure_req_fl "brake pressure request fl from GVCU to IEB - it's an offset to IEB's target pressure";
CM_ SG_ 480 brake_pressure_req_fr "brake pressure request fr from GVCU to IEB - it's an offset to IEB's target pressure";
CM_ SG_ 480 brake_pressure_req_rl "brake pressurerequest rl from GVCU to IEB - it's an offset to IEB's target pressure";
CM_ SG_ 480 brake_pressure_req_rr "brake pressure request rr from GVCU to IEB - it's an offset to IEB's target pressure";
CM_ BO_ 483 "Requested regen brake torque from IEB to GVCU";
CM_ SG_ 483 e2e_checksum "CRC check value according to specification E2E";
CM_ SG_ 483 e2e_alive_counter "Alive counter for E2E";
CM_ SG_ 483 reg_sts "status bit indicating if regen is active";
CM_ SG_ 483 recu_brake_torque_req_v "Valid signal of RecuBrakeTorqueReq";
CM_ SG_ 483 recu_brake_torque_req "IEB will convert the target braking force into the recovered torque of the motor and request the motor to execute according to the driver's braking request";
CM_ BO_ 484 "Actual regen brake torque from GVCU to IEB";
CM_ SG_ 484 e2e_checksum "CRC check value according to specification E2E";
CM_ SG_ 484 e2e_alive_counter "Alive counter for E2E";
CM_ SG_ 484 max_regen_torque_v "Valid signal for SetMaxRegenTorque";
CM_ SG_ 484 recu_brake_torque_act_v "Valid signal for RecuBrakeTorqueAct";
CM_ SG_ 484 max_regen_torque "SetMaxRegenTorque is the maximum torque recovery capability fed back by the motor. IEB will limit the internally calculated request torque recovery based on this signal.";
CM_ SG_ 484 recu_brake_torque_act "Recuperation Brake Torque Actual at wheel";
CM_ BO_ 512 "ACC State Request by the GVCU and driver inputs";
CM_ SG_ 512 e2e_checksum "CRC check value according to specification E2E";
CM_ SG_ 512 e2e_alive_counter "Alive counter for E2E";
CM_ SG_ 512 acc_sys_st "ACC System State";
CM_ SG_ 512 acc_actr_resp "ACC System Actuator Response";
CM_ SG_ 512 acc_req_dist_lvl "ACC Driver Request Time-Distance Level";
CM_ SG_ 512 acc_reqd_crs_vel_v "Driver Requested Cruise Velocity Valid";
CM_ SG_ 512 clstr_dspd_veh_vel_v "Cluster Displayed Vehicle Velocity Valid";
CM_ SG_ 512 actuator_req_val_fb_v "ACC System acceleration request feedback Valid";
CM_ SG_ 512 acc_reqd_crs_vel "Driver Requested Cruise Velocity";
CM_ SG_ 512 clstr_dspd_veh_vel "Cluster Displayed Vehicle Velocity";
CM_ SG_ 512 actuator_req_val_fb "ACC System acceleration request feedback";
CM_ BO_ 513 "ACC System Control message";
CM_ SG_ 513 e2e_checksum "CRC check value according to specification E2E";
CM_ SG_ 513 e2e_alive_counter "Alive counter for E2E";
CM_ SG_ 513 fwd_veh_detd "ACC System detected Forward Vehicle";
CM_ SG_ 513 stationary_req "ACC System stationary request";
CM_ SG_ 513 actuator_req_val "ACC System acceleration request";
CM_ SG_ 513 actuator_req_val_v "ACC System acceleration request Valid";
CM_ SG_ 513 driver_takeover_req "ACC Driver Takeover Request";
CM_ BO_ 514 "ACC System related Vehicle Systems Status";
CM_ SG_ 514 e2e_checksum "CRC check value according to specification E2E";
CM_ SG_ 514 e2e_alive_counter "Alive counter for E2E";
CM_ SG_ 514 veh_rollg_st "Vehicle Rolling State";
CM_ SG_ 514 rvs_indcr "Reverse Indicator Status";
CM_ SG_ 514 abs_st "ABS status 
- UNKNOWN if no info are available 
- UNAVAILABLE if either OFF or has FAILURE 
- AVAILABLE if it is ON but not Intervening 
- ACTIVE if it is ON and Intervening ";
CM_ SG_ 514 tcs_st "TC status 
- UNKNOWN if no info are available 
- UNAVAILABLE if either OFF or has FAILURE 
- AVAILABLE if it is ON but not Intervening 
- ACTIVE if it is ON and Intervening ";
CM_ SG_ 514 wiper_st "Front Wiper Status";
CM_ SG_ 514 drvr_brk_req "Driver Brake Request";
CM_ SG_ 514 turn_swc_st "Turn Switch Status";
CM_ SG_ 514 high_beam_actv "High Beam Active";
CM_ SG_ 514 fog_light_actv "Fog Light Active";
CM_ SG_ 514 brk_pedl_psd "Brake Pedal is Pressed";
CM_ SG_ 514 park_gear_indcr "Park Gear Indicator";
CM_ SG_ 514 veh_vel_lgt_v "Vehicle Longitudinal Velocity Valid";
CM_ SG_ 514 accel_pedl_perc "Accelerator pedal percentage";
CM_ SG_ 514 veh_vel_lgt "Vehicle Longitudinal Velocity";
CM_ BO_ 515 "ACC System Forward Vehicle ID=1 info";
CM_ SG_ 515 e2e_checksum "CRC check value according to specification E2E";
CM_ SG_ 515 e2e_alive_counter "Alive counter for E2E";
CM_ SG_ 515 fwd_veh_id1_class "ACC System Followed Vehicle Class";
CM_ SG_ 515 fwd_veh_id1_detd "ACC System Forward Vehicle ID1 Detected";
CM_ SG_ 515 fwd_veh_id1_dist_lgt "ACC System Followed Vehicle Longitudinal Distance";
CM_ SG_ 515 fwd_veh_id1_dist_lat "ACC System Followed Vehicle Lateral Distance";
CM_ SG_ 515 fwd_veh_id1_dist_v "ACC System Followed Vehicle Distance Valid";
CM_ SG_ 515 fwd_veh_id1_rel_vel "ACC System Followed Vehicle Relative Velocity";
CM_ SG_ 515 fwd_veh_id1_rel_vel_v "ACC System Followed Vehicle Relative Velocity Valid";
CM_ BO_ 516 "ACC System Detected Vehicle ID=2 info";
CM_ SG_ 516 e2e_checksum "CRC check value according to specification E2E";
CM_ SG_ 516 e2e_alive_counter "Alive counter for E2E";
CM_ SG_ 516 veh_obj_id2_class "ACC System Vehicle Object ID2 Class";
CM_ SG_ 516 veh_obj_id2_dist_lgt "ACC System Vehicle Object ID2 Longitudinal Distance";
CM_ SG_ 516 veh_obj_id2_detd "ACC System Vehicle Object ID2 Detected";
CM_ SG_ 516 veh_obj_id2_dist_lat "ACC System Vehicle Object ID2 Lateral Distance";
CM_ SG_ 516 veh_obj_id2_dist_v "ACC System Vehicle Object ID2 Distance Valid";
CM_ BO_ 517 "ACC System Detected Vehicle ID=3 info";
CM_ SG_ 517 e2e_checksum "CRC check value according to specification E2E";
CM_ SG_ 517 e2e_alive_counter "Alive counter for E2E";
CM_ SG_ 517 veh_obj_id3_class "ACC System Vehicle Object ID3 Class";
CM_ SG_ 517 veh_obj_id3_dist_lgt "ACC System Vehicle Object ID3 Longitudinal Distance";
CM_ SG_ 517 veh_obj_id3_detd "ACC System Vehicle Object ID3 Detected";
CM_ SG_ 517 veh_obj_id3_dist_lat "ACC System Vehicle Object ID3 Lateral Distance";
CM_ SG_ 517 veh_obj_id3_dist_v "ACC System Vehicle Object ID3 Distance Valid";
CM_ BO_ 518 "ACC System Detected Vehicle ID=4 info";
CM_ SG_ 518 e2e_checksum "CRC check value according to specification E2E";
CM_ SG_ 518 e2e_alive_counter "Alive counter for E2E";
CM_ SG_ 518 veh_obj_id4_class "ACC System Vehicle Object ID4 Class";
CM_ SG_ 518 veh_obj_id4_dist_lgt "ACC System Vehicle Object ID4 Longitudinal Distance";
CM_ SG_ 518 veh_obj_id4_detd "ACC System Vehicle Object ID4 Detected";
CM_ SG_ 518 veh_obj_id4_dist_lat "ACC System Vehicle Object ID4 Lateral Distance";
CM_ SG_ 518 veh_obj_id4_dist_v "ACC System Vehicle Object ID4 Distance Valid";
CM_ BO_ 519 "ACC Error message";
CM_ SG_ 519 e2e_checksum "CRC check value according to specification E2E";
CM_ SG_ 519 e2e_alive_counter "Alive counter for E2E";
CM_ SG_ 519 acc_camera_blk_sts "Is camera blocked";
CM_ SG_ 519 fvcm_internal_sc "FVCM internal 5V/ 3.3V/1.8V/1.1V/1.0V is overvoltage or undervoltage for 500ms";
CM_ SG_ 519 fvcm_pll_oor "FVCM MCU PLL is out-of-range";
CM_ SG_ 519 fvcm_gpio_err "FVCM ErrorOut GPIO is high level";
CM_ SG_ 519 fvcm_mem_fail "FVCM flash, ram or NVM test fail ";
CM_ SG_ 519 eyeq_boot_err "EyeQ reports the error value of BootDiag Fatal Error";
CM_ SG_ 519 eyeq_app_msg_timeout "EyeQ has no app msg output within 500ms";
CM_ SG_ 519 eyeq_uncalibrated "EyeQ reports to be uncalibrated";
CM_ SG_ 519 eyeq_out_of_cal "EyeQ Image Process Unit reports out-of-calibration for 2 times";
CM_ SG_ 519 eyeq_out_of_rng "EyeQ Image Process Unit report Autofix-out-of-range is true for 2 times";
CM_ SG_ 519 eyeq_out_of_focus "EyeQ Image Process Ubit reports Out of Focus";
CM_ SG_ 519 fvcm_bus_off "FVCM bus is off";
CM_ SG_ 519 fvcm_pwr_mod_invalid "FVCM PowerMode is invalid";
CM_ SG_ 519 acc_camera_blkd_rsn_mask "Camera blocked reason mask";
CM_ BO_ 520 "ACC System Lane 0 Info";
CM_ SG_ 520 e2e_checksum "CRC check value according to specification E2E";
CM_ SG_ 520 e2e_alive_counter "Alive counter for E2E";
CM_ SG_ 520 lane0_id "ACC System Lane 0 Identifier";
CM_ SG_ 520 lane0_location "ACC System Lane 0 Location";
CM_ SG_ 520 lane0_type "ACC System Lane 0 Marker Type";
CM_ SG_ 520 lane0_colour "ACC System Lane 0 Colour";
CM_ SG_ 520 lane0_view_range_start "ACC System Lane 0 Longitudinal Starting Distance";
CM_ SG_ 520 lane0_view_range_stop "ACC System Lane 0 Longitudinal Ending Distance";
CM_ SG_ 520 lane0_exist_prob "ACC System Lane 0 Probability to exist (1 max value)";
CM_ BO_ 521 "ACC System Lane 0 Parameters";
CM_ SG_ 521 e2e_checksum "CRC check value according to specification E2E";
CM_ SG_ 521 e2e_alive_counter "Alive counter for E2E";
CM_ SG_ 521 lane0_sync_counter "ACC System Lane 0 Synchronize Counter";
CM_ SG_ 521 lane0_C0 "ACC System Lane 0 Curve Parameter C0  
Lane equation: y = C0 + C1*x + (1/2)*C2*x^2 + (1/6)*C3*x^3  
\"x\" longitudinal distance [m]  
\"y\" lateral distance [m]";
CM_ SG_ 521 lane0_C1 "ACC System Lane 0 Curve Parameter C1  
Lane equation: y = C0 + C1*x + (1/2)*C2*x^2 + (1/6)*C3*x^3  
\"x\" longitudinal distance [m]  
\"y\" lateral distance [m]";
CM_ SG_ 521 lane0_C2 "ACC System Lane 0 Curve Parameter C2  
Lane equation: y = C0 + C1*x + (1/2)*C2*x^2 + (1/6)*C3*x^3  
\"x\" longitudinal distance [m]  
\"y\" lateral distance [m]";
CM_ SG_ 521 lane0_C3 "ACC System Lane 0 Curve Parameter C3  
Lane equation: y = C0 + C1*x + (1/2)*C2*x^2 + (1/6)*C3*x^3  
\"x\" longitudinal distance [m]  
\"y\" lateral distance [m]";
CM_ BO_ 522 "ACC System Lane 1 Info";
CM_ SG_ 522 e2e_checksum "CRC check value according to specification E2E";
CM_ SG_ 522 e2e_alive_counter "Alive counter for E2E";
CM_ SG_ 522 lane1_id "ACC System Lane 1 Identifier";
CM_ SG_ 522 lane1_location "ACC System Lane 1 Location";
CM_ SG_ 522 lane1_type "ACC System Lane 1 Marker Type";
CM_ SG_ 522 lane1_colour "ACC System Lane 1 Colour";
CM_ SG_ 522 lane1_view_range_start "ACC System Lane 1 Longitudinal Starting Distance";
CM_ SG_ 522 lane1_view_range_stop "ACC System Lane 1 Longitudinal Ending Distance";
CM_ SG_ 522 lane1_exist_prob "ACC System Lane 1 Probability to exist (1 max value)";
CM_ BO_ 523 "ACC System Lane 1 Parameters";
CM_ SG_ 523 e2e_checksum "CRC check value according to specification E2E";
CM_ SG_ 523 e2e_alive_counter "Alive counter for E2E";
CM_ SG_ 523 lane1_sync_counter "ACC System Lane 1 Synchronize Counter";
CM_ SG_ 523 lane1_C0 "ACC System Lane 1 Curve Parameter C0  
Lane equation: y = C0 + C1*x + (1/2)*C2*x^2 + (1/6)*C3*x^3  
\"x\" longitudinal distance [m]  
\"y\" lateral distance [m]";
CM_ SG_ 523 lane1_C1 "ACC System Lane 1 Curve Parameter C1  
Lane equation: y = C0 + C1*x + (1/2)*C2*x^2 + (1/6)*C3*x^3  
\"x\" longitudinal distance [m]  
\"y\" lateral distance [m]";
CM_ SG_ 523 lane1_C2 "ACC System Lane 1 Curve Parameter C2  
Lane equation: y = C0 + C1*x + (1/2)*C2*x^2 + (1/6)*C3*x^3  
\"x\" longitudinal distance [m]  
\"y\" lateral distance [m]";
CM_ SG_ 523 lane1_C3 "ACC System Lane 1 Curve Parameter C3  
Lane equation: y = C0 + C1*x + (1/2)*C2*x^2 + (1/6)*C3*x^3  
\"x\" longitudinal distance [m]  
\"y\" lateral distance [m]";
CM_ BO_ 524 "ACC System Lane 2 Info";
CM_ SG_ 524 e2e_checksum "CRC check value according to specification E2E";
CM_ SG_ 524 e2e_alive_counter "Alive counter for E2E";
CM_ SG_ 524 lane2_id "ACC System Lane 2 Identifier";
CM_ SG_ 524 lane2_location "ACC System Lane 2 Location";
CM_ SG_ 524 lane2_type "ACC System Lane 2 Marker Type";
CM_ SG_ 524 lane2_colour "ACC System Lane 2 Colour";
CM_ SG_ 524 lane2_view_range_start "ACC System Lane 2 Longitudinal Starting Distance";
CM_ SG_ 524 lane2_view_range_stop "ACC System Lane 2 Longitudinal Ending Distance";
CM_ SG_ 524 lane2_exist_prob "ACC System Lane 2 Probability to exist (1 max value)";
CM_ BO_ 525 "ACC System Lane 2 Parameters";
CM_ SG_ 525 e2e_checksum "CRC check value according to specification E2E";
CM_ SG_ 525 e2e_alive_counter "Alive counter for E2E";
CM_ SG_ 525 lane2_sync_counter "ACC System Lane 2 Synchronize Counter";
CM_ SG_ 525 lane2_C0 "ACC System Lane 2 Curve Parameter C0  
Lane equation: y = C0 + C1*x + (1/2)*C2*x^2 + (1/6)*C3*x^3  
\"x\" longitudinal distance [m]  
\"y\" lateral distance [m]";
CM_ SG_ 525 lane2_C1 "ACC System Lane 2 Curve Parameter C1  
Lane equation: y = C0 + C1*x + (1/2)*C2*x^2 + (1/6)*C3*x^3  
\"x\" longitudinal distance [m]  
\"y\" lateral distance [m]";
CM_ SG_ 525 lane2_C2 "ACC System Lane 2 Curve Parameter C2  
Lane equation: y = C0 + C1*x + (1/2)*C2*x^2 + (1/6)*C3*x^3  
\"x\" longitudinal distance [m]  
\"y\" lateral distance [m]";
CM_ SG_ 525 lane2_C3 "ACC System Lane 2 Curve Parameter C3  
Lane equation: y = C0 + C1*x + (1/2)*C2*x^2 + (1/6)*C3*x^3  
\"x\" longitudinal distance [m]  
\"y\" lateral distance [m]";
CM_ BO_ 528 "ACC System Lane 3 Info";
CM_ SG_ 528 e2e_checksum "CRC check value according to specification E2E";
CM_ SG_ 528 e2e_alive_counter "Alive counter for E2E";
CM_ SG_ 528 lane3_id "ACC System Lane 3 Identifier";
CM_ SG_ 528 lane3_location "ACC System Lane 3 Location";
CM_ SG_ 528 lane3_type "ACC System Lane 3 Marker Type";
CM_ SG_ 528 lane3_colour "ACC System Lane 3 Colour";
CM_ SG_ 528 lane3_view_range_start "ACC System Lane 3 Longitudinal Starting Distance";
CM_ SG_ 528 lane3_view_range_stop "ACC System Lane 3 Longitudinal Ending Distance";
CM_ SG_ 528 lane3_exist_prob "ACC System Lane 3 Probability to exist (1 max value)";
CM_ BO_ 529 "ACC System Lane 3 Parameters";
CM_ SG_ 529 e2e_checksum "CRC check value according to specification E2E";
CM_ SG_ 529 e2e_alive_counter "Alive counter for E2E";
CM_ SG_ 529 lane3_sync_counter "ACC System Lane 3 Synchronize Counter";
CM_ SG_ 529 lane3_C0 "ACC System Lane 3 Curve Parameter C0  
Lane equation: y = C0 + C1*x + (1/2)*C2*x^2 + (1/6)*C3*x^3  
\"x\" longitudinal distance [m]  
\"y\" lateral distance [m]";
CM_ SG_ 529 lane3_C1 "ACC System Lane 3 Curve Parameter C1  
Lane equation: y = C0 + C1*x + (1/2)*C2*x^2 + (1/6)*C3*x^3  
\"x\" longitudinal distance [m]  
\"y\" lateral distance [m]";
CM_ SG_ 529 lane3_C2 "ACC System Lane 3 Curve Parameter C2  
Lane equation: y = C0 + C1*x + (1/2)*C2*x^2 + (1/6)*C3*x^3  
\"x\" longitudinal distance [m]  
\"y\" lateral distance [m]";
CM_ SG_ 529 lane3_C3 "ACC System Lane 3 Curve Parameter C3  
Lane equation: y = C0 + C1*x + (1/2)*C2*x^2 + (1/6)*C3*x^3  
\"x\" longitudinal distance [m]  
\"y\" lateral distance [m]";
CM_ BO_ 1470 "error counter status message";
CM_ SG_ 1470 e2e_crc_err_cnt "IEB e2e crc error counter";
CM_ SG_ 1470 e2e_alive_cnt_err_cnt "IEB alive error counter";
CM_ SG_ 1470 sa_fail_attempt_cnt "IEB security access fail attempt counter";
CM_ BO_ 1471 "error counter status message";
CM_ SG_ 1471 e2e_crc_err_cnt "ACC e2e crc error counter";
CM_ SG_ 1471 e2e_alive_cnt_err_cnt "ACC e2e alive error counter";
CM_ SG_ 1471 sa_fail_attempt_cnt "ACC security access fail attempt counter";
CM_ BO_ 1500 "odometer value";
CM_ SG_ 1500 e2e_checksum "CRC check value according to specification E2E";
CM_ SG_ 1500 e2e_alive_counter "Alive counter for E2E";
CM_ SG_ 1500 veh_odo_v "Vehicle odometer qualifier";
CM_ SG_ 1500 veh_odo "Vehicle odometer sent by GVCU";
CM_ BO_ 1507 "System Power Mode";
CM_ SG_ 1507 e2e_checksum "CRC check value according to specification E2E";
CM_ SG_ 1507 e2e_alive_counter "Alive counter for E2E";
CM_ SG_ 1507 kl30_voltage_v "KL30 LV battery voltage valid signal";
CM_ SG_ 1507 kl30_voltage "KL30 LV battery voltage";
CM_ SG_ 1507 kl15_sts "KL15 status, equal to ON when Ignition is ON and traction power is available";
CM_ SG_ 1507 kl30_charging "KL30 LV battery is being charged, either by external charger or onboard DCDC";
CM_ SG_ 1507 kl50_sts "KL50, equal to ON when the ICE is in cranking state";
CM_ SG_ 1507 klr_sts "KLR, equal to ON when LV systems are turned ON but there is no traction power available";
CM_ BO_ 1510 "Network management request from GVCU";
CM_ SG_ 1510 e2e_checksum "CRC check value according to specification E2E";
CM_ SG_ 1510 e2e_alive_counter "Alive counter for E2E";
CM_ SG_ 1510 nm_request "Network management request from GVCU";
CM_ BO_ 1513 "IEB network management status for CAN wakeup";
CM_ SG_ 1513 e2e_checksum "CRC check value according to specification E2E";
CM_ SG_ 1513 e2e_alive_counter "Alive counter for E2E";
CM_ SG_ 1513 nm_status "IEB network management status sent by IEB";
CM_ BO_ 1515 "ACC System Network Management";
CM_ SG_ 1515 e2e_checksum "CRC check value according to specification E2E";
CM_ SG_ 1515 e2e_alive_counter "Alive counter for E2E";
CM_ SG_ 1515 nm_status "ACC network management status sent by ACC";
CM_ BO_ 1518 "system time";
CM_ SG_ 1518 e2e_checksum "CRC check value according to specification E2E";
CM_ SG_ 1518 e2e_alive_counter "Alive counter for E2E";
CM_ BO_ 1614 "IEB XCP Command";
CM_ BO_ 1615 "IEB XCP Response";
CM_ BO_ 1821 "Conti IMU - message can't be changed";
CM_ SG_ 1821 yaw_rate "yaw rate";
CM_ SG_ 1821 yaw_rate_qual "yaw rate quality";
CM_ SG_ 1821 lat_acc_qual "Lateral acceleration (Y-axis) quality";
CM_ SG_ 1821 lat_acc "Lateral acceleration (Y-axis)";
CM_ BO_ 1822 "Conti IMU - message can't be changed";
CM_ SG_ 1822 roll_rate "roll rate";
CM_ SG_ 1822 roll_rate_qual "roll rate quality";
CM_ SG_ 1822 long_acc_qual "Longitudal acceleration (X-axis) quality";
CM_ SG_ 1822 long_acc "Longitudal acceleration (X-axis)";
CM_ BO_ 1823 "Conti IMU - message can't be changed";
CM_ SG_ 1823 pitch_rate "pitch rate";
CM_ SG_ 1823 pitch_rate_qual "pitch rate quality";
CM_ SG_ 1823 vert_acc_qual "vertical acceleration quality";
CM_ SG_ 1823 vert_acc "vertical acceleration";
CM_ BO_ 1831 "Conti IMU - message can't be changed";
CM_ BO_ 1832 "Conti IMU - message can't be changed";
CM_ BO_ 1890 "Conti IMU - message can't be changed";
CM_ BO_ 1891 "Conti IMU - message can't be changed";
CM_ BO_ 1989 "Diag Req IEB";
CM_ BO_ 1995 "ACC Diagnostic Request";
CM_ BO_ 1997 "Diag Resp IEB";
CM_ BO_ 2002 "ACC Diagnostic Response";
CM_ BO_ 2003 "ACC Diagnostic";
CM_ SG_ 2003 dtc_severity_level "DTC Severity Level, Values 5-15 are reserved";
CM_ SG_ 2003 dtc_high_byte "High byte of DTC";
CM_ SG_ 2003 dtc_low_byte "Low byte of DTC";
CM_ SG_ 2003 dtc_failure_type_byte "Failure type byte of DTC";
CM_ SG_ 2003 dtc_type "DTC Type values 7-255 are reserved";
CM_ BO_ 2006 "Dynamic Bus 1 & 2 Diagnostic Request";
BA_DEF_  "BusSpeed" INT 0 2000000;
BA_DEF_ SG_  "CheckSigRange" ENUM  "NO","YES";
BA_DEF_ BO_  "DiagRequest" ENUM  "no","yes";
BA_DEF_ BO_  "DiagResponse" ENUM  "no","yes";
BA_DEF_ BO_  "DiagState" ENUM  "no","yes";
BA_DEF_ BO_  "GatewayMode" ENUM  "GW_OFF","GW_ONLY","GW_RECV";
BA_DEF_ BO_  "GenMsgCycleTime" INT 0 0;
BA_DEF_ BO_  "GenMsgSendType" ENUM  "cyclic","event","NoMsgSendType";
BA_DEF_ SG_  "GenSigSendType" ENUM  "Cyclic","OnWrite","OnWriteWithRepetition","OnChange","OnChangeWithRepetition","IfActive","IfActiveWithRepetition","NoSigSendType","NotUsed","NotUsed","NotUsed","NotUsed","NotUsed";
BA_DEF_ SG_  "GenSigStartValue" INT -999999 999999;
BA_DEF_ BO_  "NmMessage" ENUM  "no","yes";
BA_DEF_DEF_  "BusSpeed" 500000;
BA_DEF_DEF_  "CheckSigRange" "YES";
BA_DEF_DEF_  "DiagRequest" "no";
BA_DEF_DEF_  "DiagResponse" "no";
BA_DEF_DEF_  "DiagState" "no";
BA_DEF_DEF_  "GatewayMode" "GW_OFF";
BA_DEF_DEF_  "GenMsgCycleTime" 0;
BA_DEF_DEF_  "GenMsgSendType" "cyclic";
BA_DEF_DEF_  "GenSigSendType" "NoSigSendType";
BA_DEF_DEF_  "GenSigStartValue" 0;
BA_DEF_DEF_  "NmMessage" "no";
BA_ "GenMsgCycleTime" BO_ 194 10;
BA_ "GenMsgCycleTime" BO_ 260 10;
BA_ "GenMsgCycleTime" BO_ 269 10;
BA_ "GenMsgCycleTime" BO_ 270 10;
BA_ "GenMsgCycleTime" BO_ 450 10;
BA_ "GenMsgCycleTime" BO_ 451 5;
BA_ "GenMsgCycleTime" BO_ 452 5;
BA_ "GenMsgCycleTime" BO_ 453 10;
BA_ "GenMsgCycleTime" BO_ 454 100;
BA_ "GenMsgCycleTime" BO_ 455 100;
BA_ "GenMsgCycleTime" BO_ 457 100;
BA_ "GenMsgCycleTime" BO_ 459 10;
BA_ "GenMsgCycleTime" BO_ 461 10;
BA_ "GenMsgCycleTime" BO_ 462 10;
BA_ "GenMsgCycleTime" BO_ 464 20;
BA_ "GenMsgCycleTime" BO_ 465 100;
BA_ "GenMsgCycleTime" BO_ 467 10;
BA_ "GenMsgCycleTime" BO_ 472 10;
BA_ "GenMsgCycleTime" BO_ 475 10;
BA_ "GenMsgCycleTime" BO_ 478 10;
BA_ "GenMsgCycleTime" BO_ 479 10;
BA_ "GenMsgCycleTime" BO_ 480 10;
BA_ "GenMsgCycleTime" BO_ 483 10;
BA_ "GenMsgCycleTime" BO_ 484 10;
BA_ "GenMsgCycleTime" BO_ 512 20;
BA_ "GenMsgCycleTime" BO_ 513 20;
BA_ "GenMsgCycleTime" BO_ 514 20;
BA_ "GenMsgCycleTime" BO_ 515 20;
BA_ "GenMsgCycleTime" BO_ 516 100;
BA_ "GenMsgCycleTime" BO_ 517 100;
BA_ "GenMsgCycleTime" BO_ 518 100;
BA_ "GenMsgCycleTime" BO_ 519 100;
BA_ "GenMsgCycleTime" BO_ 520 100;
BA_ "GenMsgCycleTime" BO_ 521 100;
BA_ "GenMsgCycleTime" BO_ 522 100;
BA_ "GenMsgCycleTime" BO_ 523 100;
BA_ "GenMsgCycleTime" BO_ 524 100;
BA_ "GenMsgCycleTime" BO_ 525 100;
BA_ "GenMsgCycleTime" BO_ 528 100;
BA_ "GenMsgCycleTime" BO_ 529 100;
BA_ "GenMsgCycleTime" BO_ 1470 1000;
BA_ "GenMsgCycleTime" BO_ 1471 1000;
BA_ "GenMsgCycleTime" BO_ 1500 100;
BA_ "GenMsgCycleTime" BO_ 1507 100;
BA_ "GenMsgCycleTime" BO_ 1510 100;
BA_ "NmMessage" BO_ 1510 1;
BA_ "GenMsgCycleTime" BO_ 1513 100;
BA_ "NmMessage" BO_ 1513 1;
BA_ "GenMsgCycleTime" BO_ 1515 100;
BA_ "NmMessage" BO_ 1515 1;
BA_ "GenMsgCycleTime" BO_ 1518 500;
BA_ "GenMsgSendType" BO_ 1614 1;
BA_ "GenMsgSendType" BO_ 1615 1;
BA_ "GenMsgCycleTime" BO_ 1821 10;
BA_ "GenMsgCycleTime" BO_ 1822 10;
BA_ "GenMsgCycleTime" BO_ 1823 10;
BA_ "GenMsgCycleTime" BO_ 1831 500;
BA_ "GenMsgCycleTime" BO_ 1832 500;
BA_ "GatewayMode" BO_ 1890 1;
BA_ "GenMsgSendType" BO_ 1890 1;
BA_ "GatewayMode" BO_ 1891 1;
BA_ "GenMsgSendType" BO_ 1891 1;
BA_ "GatewayMode" BO_ 1989 1;
BA_ "GenMsgSendType" BO_ 1989 1;
BA_ "DiagRequest" BO_ 1995 1;
BA_ "GatewayMode" BO_ 1995 1;
BA_ "GenMsgSendType" BO_ 1995 1;
BA_ "GatewayMode" BO_ 1997 1;
BA_ "GenMsgSendType" BO_ 1997 1;
BA_ "DiagResponse" BO_ 2002 1;
BA_ "GatewayMode" BO_ 2002 1;
BA_ "GenMsgSendType" BO_ 2002 1;
BA_ "GatewayMode" BO_ 2003 1;
BA_ "GenMsgSendType" BO_ 2003 1;
BA_ "DiagState" BO_ 2006 1;
BA_ "GatewayMode" BO_ 2006 1;
BA_ "GenMsgSendType" BO_ 2006 1;
BA_ "GenSigStartValue" SG_ 459 position_motor 20;
BA_ "GenSigStartValue" SG_ 464 driver_torque_rqst 2044;
BA_ "GenSigStartValue" SG_ 467 steering_wheel_angle 7800;
BA_ "GenSigStartValue" SG_ 467 steering_wheel_rot_speed 10160;
BA_ "GenSigStartValue" SG_ 472 yaw_rate 32766;
BA_ "GenSigStartValue" SG_ 472 lat_acc 32766;
BA_ "GenSigStartValue" SG_ 472 long_acc 32766;
BA_ "GenSigStartValue" SG_ 478 wheel_torque_act_fl 32767;
BA_ "GenSigStartValue" SG_ 478 wheel_torque_act_fr 32767;
BA_ "GenSigStartValue" SG_ 479 wheel_torque_act_rl 32767;
BA_ "GenSigStartValue" SG_ 479 wheel_torque_act_rr 32767;
BA_ "GenSigStartValue" SG_ 1821 lat_acc 32766;
BA_ "GenSigStartValue" SG_ 1821 temperature 50;
VAL_ 194 angle_direction 0 "CCW" 1 "CW" ;
VAL_ 194 angle_rate_direction 0 "CCW" 1 "CW" ;
VAL_ 270 whl_tq_fric_brk_fl_v 0 "NOT_VALID" 1 "VALID" ;
VAL_ 270 whl_tq_fric_brk_fr_v 0 "NOT_VALID" 1 "VALID" ;
VAL_ 270 whl_tq_fric_brk_rl_v 0 "NOT_VALID" 1 "VALID" ;
VAL_ 270 whl_tq_fric_brk_rr_v 0 "NOT_VALID" 1 "VALID" ;
VAL_ 450 e2e_alive_counter 15 "INVALID" ;
VAL_ 450 vehicle_speed_r_v 0 "NOT_VALID" 1 "VALID" ;
VAL_ 451 e2e_alive_counter 15 "INVALID" ;
VAL_ 451 wheel_rate_fl_v 0 "NOT_VALID" 1 "VALID" ;
VAL_ 451 wheel_rate_fr_v 0 "NOT_VALID" 1 "VALID" ;
VAL_ 451 wheel_direction_fl 0 "UNKNOWN" 1 "UNAVAILABLE" 2 "STANDSTILL" 3 "FORWARDS" 4 "BACKWARDS" 5 "OVERSPEED" ;
VAL_ 451 wheel_direction_fr 0 "UNKNOWN" 1 "UNAVAILABLE" 2 "STANDSTILL" 3 "FORWARDS" 4 "BACKWARDS" 5 "OVERSPEED" ;
VAL_ 452 e2e_alive_counter 15 "INVALID" ;
VAL_ 452 wheel_rate_rl_v 0 "NOT_VALID" 1 "VALID" ;
VAL_ 452 wheel_rate_rr_v 0 "NOT_VALID" 1 "VALID" ;
VAL_ 452 wheel_direction_rl 0 "UNKNOWN" 1 "UNAVAILABLE" 2 "STANDSTILL" 3 "FORWARDS" 4 "BACKWARDS" 5 "OVERSPEED" ;
VAL_ 452 wheel_direction_rr 0 "UNKNOWN" 1 "UNAVAILABLE" 2 "STANDSTILL" 3 "FORWARDS" 4 "BACKWARDS" 5 "OVERSPEED" ;
VAL_ 453 e2e_alive_counter 15 "INVALID" ;
VAL_ 453 wss_status_fl 0 "UNKNOWN" 1 "SHORT_TO_GND" 2 "OPEN_CIRCUIT" 3 "GAP_TOO_LARGE" 4 "GAP_TOO_SMALL" 5 "ENCODER_WHEEL_DAMAGED" 6 "OPERATIONAL" ;
VAL_ 453 wss_status_fr 0 "UNKNOWN" 1 "SHORT_TO_GND" 2 "OPEN_CIRCUIT" 3 "GAP_TOO_LARGE" 4 "GAP_TOO_SMALL" 5 "ENCODER_WHEEL_DAMAGED" 6 "OPERATIONAL" ;
VAL_ 453 wss_status_rl 0 "UNKNWON" 1 "SHORT_TO_GND" 2 "OPEN_CIRCUIT" 3 "GAP_TOO_LARGE" 4 "GAP_TOO_SMALL" 5 "ENCODER_WHEEL_DAMAGED" 6 "OPERATIONAL" ;
VAL_ 453 wss_status_rr 0 "UNKNOWN" 1 "SHORT_TO_GND" 2 "OPEN_CIRCUIT" 3 "GAP_TOO_LARGE" 4 "GAP_TOO_SMALL" 5 "ENCODER_WHEEL_DAMAGED" 6 "OPERATIONAL" ;
VAL_ 454 e2e_alive_counter 15 "INVALID" ;
VAL_ 454 brake_booster_telltale 0 "UNKNOWN" 1 "ENABLED" 2 "DISABLED" ;
VAL_ 454 abs_telltale 0 "UNKNOWN" 1 "ENABLED" 2 "DISABLED" ;
VAL_ 454 pressure_diagnostic 0 "UNKNOWN" 1 "UNAVAILABLE" 2 "PRESSURE_ERROR" 3 "PRESSURE_OK" ;
VAL_ 454 vdc_off_telltale 0 "UNKNOWN" 1 "ENABLED" 2 "DISABLED" ;
VAL_ 454 temp_diagnostic 0 "UNKNOWN" 1 "UNAVAILABLE" 2 "TEMP_ERROR" 3 "TEMP_OK" ;
VAL_ 454 diag_active 0 "UNKNOWN" 1 "DIAG_NOT_ACTIVE" 2 "DIAG_ACTIVE" ;
VAL_ 454 leakage_detection 0 "UNKNOWN" 1 "UNAVAILABLE" 2 "LEAKAGE_DETECTED" 3 "NO_LEAKAGE" ;
VAL_ 454 voltage_diagnostics 0 "UNKNOWN" 1 "UNAVAILABLE" 2 "VOLTAGE_ERROR" 3 "VOLTAGE_OK" ;
VAL_ 454 self_diagnostic 0 "UNKNOWN" 1 "UNAVAILABLE" 2 "SELF_CHECK_ERROR" 3 "SELF_CHECK_OK" ;
VAL_ 454 com_diagnostic 0 "UNKNOWN" 1 "UNAVAILABLE" 2 "COM_ERROR" 3 "COM_OK" ;
VAL_ 454 ieb_deg_sts 0 "UNKNOWN" 1 "DEGRADE_1" 2 "DEGRADE_2" 3 "HYDRAULIC_BACKUP" 4 "NORMAL_OPERATION" ;
VAL_ 454 ieb_chg_mod_fb 0 "UNKNOWN" 1 "IEB_CHG_MOD_DISABLED" 2 "IEB_CHG_MOD_ENABLED" ;
VAL_ 455 e2e_alive_counter 15 "INVALID" ;
VAL_ 455 vdc_perf_mod_fb 0 "UNKNOWN" 1 "UNAVAILABLE" 2 "VDC_PERF_MOD_ON" 3 "VDC_PERF_MOD_INTER" 4 "VDC_PERF_MOD_OFF" ;
VAL_ 455 hhc_direction 0 "UNKNOWN" 1 "UNAVAILABLE" 2 "FRONT_UP_HILL" 3 "FRONT_DOWN_HILL" ;
VAL_ 455 cdd_sts 0 "UNKNOWN" 1 "UNAVAILABLE" 2 "AVAILABLE" 3 "ACTIVE" ;
VAL_ 455 vdc_sts 0 "UNKNOWN" 1 "UNAVAILABLE" 2 "AVAILABLE" 3 "ACTIVE" ;
VAL_ 455 hba_sts 0 "UNKNOWN" 1 "UNAVAILABLE" 2 "AVAILABLE" 3 "ACTIVE" ;
VAL_ 455 ebd_sts 0 "UNKNOWN" 1 "UNAVAILABLE" 2 "AVAILABLE" 3 "ACTIVE" ;
VAL_ 455 abs_sts 0 "UNKNOWN" 1 "UNAVAILABLE" 2 "PARTIALLY_UNAVAILABLE" 3 "AVAILABLE" 4 "ACTIVE" ;
VAL_ 455 hhc_sts 0 "UNKNOWN" 1 "UNAVAILABLE" 2 "DEACTIVATED" 3 "STANDBY" 4 "HOLD_PRESSURE" ;
VAL_ 457 e2e_alive_counter 15 "INVALID" ;
VAL_ 457 wheel_rotation_counter_fl_v 0 "NOT_VALID" 1 "VALID" ;
VAL_ 457 wheel_rotation_counter_fr_v 0 "NOT_VALID" 1 "VALID" ;
VAL_ 457 wheel_rotation_counter_rl_v 0 "NOT_VALID" 1 "VALID" ;
VAL_ 457 wheel_rotation_counter_rr_v 0 "NOT_VALID" 1 "VALID" ;
VAL_ 459 e2e_alive_counter 15 "INVALID" ;
VAL_ 459 brake_pedal_applied 0 "UNKNOWN" 1 "NOT_APPLIED" 2 "APPLIED" 3 "UNAVAILABLE" ;
VAL_ 459 brake_pedal_travel_mm_v 0 "NOT_VALID" 1 "VALID" ;
VAL_ 459 brake_pedal_travel_perc_v 0 "NOT_VALID" 1 "VALID" ;
VAL_ 459 brake_pedal_travel_sensor_sts 0 "UNKNOWN" 1 "UNAVAILABLE" 2 "SHORT_TO_GND" 3 "OPEN_CIRCUIT" 4 "OPERATIONAL" ;
VAL_ 459 active_mode 0 "UNKNOWN" 1 "UNAVAILABLE" 2 "NORMAL_BRAKE_APPLY_ASSIST_ACTIVE" 3 "PRESSURE_REDUCTION_ACTIVE" 4 "REGEN_BRAKING_ACTIVE" 5 "NO_ACTIVE_MODE" ;
VAL_ 461 e2e_alive_counter 15 "INVALID" ;
VAL_ 461 target_brake_pressure_fl_v 0 "NOT_VALID" 1 "VALID" ;
VAL_ 461 target_brake_pressure_fr_v 0 "NOT_VALID" 1 "VALID" ;
VAL_ 461 target_brake_pressure_rl_v 0 "NOT_VALID" 1 "VALID" ;
VAL_ 461 target_brake_pressure_rr_v 0 "NOT_VALID" 1 "VALID" ;
VAL_ 462 e2e_alive_counter 15 "INVALID" ;
VAL_ 462 mc_brk_pressure_v 0 "NOT_VALID" 1 "VALID" ;
VAL_ 462 support_brk_pressure_v 0 "NOT_VALID" 1 "VALID" ;
VAL_ 464 e2e_alive_counter 15 "INVALID" ;
VAL_ 464 epb_status 0 "UNKNOWN" 1 "CALIPERS_ENGAGING" 2 "CALIPERS_ENGAGED" 3 "CALIPERS_DISENGAGING" 4 "CALIPERS_DISENGAGED" 5 "FAILURE" ;
VAL_ 464 brake_booster_telltale_fb 0 "UNKNOWN" 1 "ENABLED" 2 "DISABLED" ;
VAL_ 464 vdc_off_telltale_fb 0 "UNKNOWN" 1 "ENABLED" 2 "DISABLED" ;
VAL_ 464 abs_telltale_fb 0 "UNKNOWN" 1 "ENABLED" 2 "DISABLED" ;
VAL_ 464 driver_torque_rqst_v 0 "NOT_VALID" 1 "VALID" ;
VAL_ 464 accelerator_pedal_position_v 0 "NOT_VALID" 1 "VALID" ;
VAL_ 464 accelerator_pedal_state 0 "UNKNOWN" 1 "NOT_APPLIED" 2 "APPLIED" 3 "UNAVAILABLE" ;
VAL_ 464 wiper_sts 0 "UNKNOWN" 1 "OFF" 2 "INTERMITTED" 3 "MEDIUM" 4 "FAST" ;
VAL_ 464 tc_sts 0 "UNKNOWN" 1 "OFF" 2 "AVAILABLE" 3 "INTERVENING" 4 "FAILURE" ;
VAL_ 464 seatbelt_driver_sts 0 "UNKNOWN" 1 "UNLATCHED" 2 "LATCHED" ;
VAL_ 465 e2e_alive_counter 15 "INVALID" ;
VAL_ 465 ieb_chg_mod_req 0 "UNKNOWN" 1 "IEB_CHG_MOD_DISABLED" 2 "IEB_CHG_MOD_ENABLED" ;
VAL_ 465 hhc_inhb_req 0 "UNKNOWN" 1 "HHC_INHBD" 2 "HHC_ALLWD" ;
VAL_ 465 drv_mod 0 "UNKNOWN" 1 "PARK" 2 "NEUTRAL" 3 "REVERSE" 4 "DRIVE" ;
VAL_ 465 vdc_perf_mod_req 0 "UNKNOWN" 1 "VDC_PERF_MOD_ON" 2 "VDC_PERF_MOD_INTER" 3 "VDC_PERF_MOD_OFF" ;
VAL_ 467 e2e_alive_counter 15 "INVALID" ;
VAL_ 467 steering_wheel_sensor_v 0 "NOT_VALID" 1 "VALID" ;
VAL_ 467 calibration_sts 0 "UNKNOWN" 1 "NOT_CALIBRATED" 2 "CALIBRATED" ;
VAL_ 472 e2e_alive_counter 15 "INVALID" ;
VAL_ 472 yaw_rate_v 0 "NOT_VALID" 1 "VALID" ;
VAL_ 472 lat_acc_v 0 "NOT_VALID" 1 "VALID" ;
VAL_ 472 long_acc_v 0 "NOT_VALID" 1 "VALID" ;
VAL_ 475 e2e_alive_counter 15 "INVALID" ;
VAL_ 475 brake_jerk_req 0 "UNKNOWN" 1 "NO_REQUEST" 2 "BRAKE_JERK_REQUEST" ;
VAL_ 475 prefill_req 0 "UNKNOWN" 1 "NO_REQUEST" 2 "BRAKE_PREFILL_REQUEST" ;
VAL_ 478 e2e_alive_counter 15 "INVALID" ;
VAL_ 478 wheel_torque_act_fl_v 0 "NOT_VALID" 1 "VALID" ;
VAL_ 478 wheel_torque_act_fr_v 0 "NOT_VALID" 1 "VALID" ;
VAL_ 479 e2e_alive_counter 15 "INVALID" ;
VAL_ 479 wheel_torque_act_rl_v 0 "NOT_VALID" 1 "VALID" ;
VAL_ 479 wheel_torque_act_rr_v 0 "NOT_VALID" 1 "VALID" ;
VAL_ 480 e2e_alive_counter 15 "INVALID" ;
VAL_ 480 brake_pressure_req_fl_v 0 "NOT_VALID" 1 "VALID" ;
VAL_ 480 brake_pressure_req_fr_v 0 "NOT_VALID" 1 "VALID" ;
VAL_ 480 brake_pressure_req_rl_v 0 "NOT_VALID" 1 "VALID" ;
VAL_ 480 brake_pressure_req_rr_v 0 "NOT_VALID" 1 "VALID" ;
VAL_ 483 e2e_alive_counter 15 "INVALID" ;
VAL_ 483 reg_sts 0 "UNKNOWN" 1 "NOT_ACTIVE" 2 "ACTIVE" ;
VAL_ 483 recu_brake_torque_req_v 0 "NOT_VALID" 1 "VALID" ;
VAL_ 484 e2e_alive_counter 15 "INVALID" ;
VAL_ 484 max_regen_torque_v 0 "NOT_VALID" 1 "VALID" ;
VAL_ 484 recu_brake_torque_act_v 0 "NOT_VALID" 1 "VALID" ;
VAL_ 512 e2e_alive_counter 15 "INVALID" ;
VAL_ 512 acc_sys_st 0 "ACC_ST_UNKNOWN" 1 "ACC_ST_OFF" 2 "ACC_ST_PASSIVE" 3 "ACC_ST_STBY" 4 "ACC_ST_ACTV_VEL_CTRL" 5 "ACC_ST_ACTV_FOL_CTRL" 6 "ACC_ST_ACTV_STANDG_ACTV" 7 "ACC_ST_OVRD" 8 "ACC_ST_ERROR" ;
VAL_ 512 acc_actr_resp 0 "ACC_ACTR_UNKNOWN" 1 "ACC_ACTR_NO_REQ" 2 "ACC_ACTR_HONORED" 3 "ACC_ACTR_LOST_ARBN" 4 "ACC_ACTR_NOT_ALLWD" 5 "ACC_ACTR_CDN_NOT_OK" ;
VAL_ 512 acc_req_dist_lvl 0 "ACC_DIST_LVL_UNKNOWN" 1 "ACC_DIST_LVL_1" 2 "ACC_DIST_LVL_2" 3 "ACC_DIST_LVL_3" ;
VAL_ 512 acc_reqd_crs_vel_v 0 "NOT_VALID" 1 "VALID" ;
VAL_ 512 clstr_dspd_veh_vel_v 0 "NOT_VALID" 1 "VALID" ;
VAL_ 512 actuator_req_val_fb_v 0 "NOT_VALID" 1 "VALID" ;
VAL_ 513 e2e_alive_counter 15 "INVALID" ;
VAL_ 513 fwd_veh_detd 0 "ACC_DETN_UNKNOWN" 1 "ACC_DETN_FALSE" 2 "ACC_DETN_TRUE" ;
VAL_ 513 stationary_req 0 "ACC_REQ_UNKNOWN" 1 "ACC_REQ_STATY" 2 "ACC_REQ_GO" ;
VAL_ 513 actuator_req_val_v 0 "NOT_VALID" 1 "VALID" ;
VAL_ 513 driver_takeover_req 0 "TAKEOVER_REQ_UNKNOWN" 1 "TAKEOVER_REQ_NONE" 2 "TAKEOVER_REQ_TRUE" ;
VAL_ 514 e2e_alive_counter 15 "INVALID" ;
VAL_ 514 veh_rollg_st 0 "ROLLING_UNKNOWN" 1 "ROLLING_STATIONARY" 2 "ROLLING_FORWARD" 3 "ROLLING_REARWARD" 4 "ROLLING_OVERSPEED" ;
VAL_ 514 rvs_indcr 0 "FALSE" 1 "TRUE" ;
VAL_ 514 abs_st 0 "UNKNOWN" 1 "UNAVAILABLE" 2 "AVAILABLE" 3 "ACTIVE" ;
VAL_ 514 tcs_st 0 "UNKNOWN" 1 "UNAVAILABLE" 2 "AVAILABLE" 3 "ACTIVE" ;
VAL_ 514 wiper_st 0 "OFF" 1 "INTERMITTENT" 2 "SLOW" 3 "FAST" ;
VAL_ 514 drvr_brk_req 0 "UNKNOWN" 1 "OFF" 2 "ON" ;
VAL_ 514 turn_swc_st 0 "TURN_SWC_OFF" 1 "TURN_SWC_LEFT" 2 "TURN_SWC_RIGHT" ;
VAL_ 514 high_beam_actv 0 "HIGH_BEAM_UNKNOWN" 1 "HIGH_BEAM_ACTIVE" 2 "HIGH_BEAM_OFF" ;
VAL_ 514 fog_light_actv 0 "FALSE" 1 "TRUE" ;
VAL_ 514 brk_pedl_psd 0 "FALSE" 1 "TRUE" ;
VAL_ 514 park_gear_indcr 0 "FALSE" 1 "TRUE" ;
VAL_ 514 veh_vel_lgt_v 0 "NOT_VALID" 1 "VALID" ;
VAL_ 515 e2e_alive_counter 15 "INVALID" ;
VAL_ 515 fwd_veh_id1_class 0 "VEH_TYPE_UNKNOWN" 1 "VEH_TYPE_CAR" 2 "VEH_TYPE_TRUCK" 3 "VEH_TYPE_BICYCLE" 4 "VEH_TYPE_MOTORCYCLE" ;
VAL_ 515 fwd_veh_id1_detd 0 "ACC_DETN_UNKNOWN" 1 "ACC_DETN_FALSE" 2 "ACC_DETN_TRUE" ;
VAL_ 515 fwd_veh_id1_dist_v 0 "NOT_VALID" 1 "VALID" ;
VAL_ 515 fwd_veh_id1_rel_vel_v 0 "NOT_VALID" 1 "VALID" ;
VAL_ 516 e2e_alive_counter 15 "INVALID" ;
VAL_ 516 veh_obj_id2_class 0 "VEH_TYPE_UNKNOWN" 1 "VEH_TYPE_CAR" 2 "VEH_TYPE_TRUCK" 3 "VEH_TYPE_BICYCLE" 4 "VEH_TYPE_MOTORCYCLE" ;
VAL_ 516 veh_obj_id2_detd 0 "ACC_DETN_UNKNOWN" 1 "ACC_DETN_FALSE" 2 "ACC_DETN_TRUE" ;
VAL_ 516 veh_obj_id2_dist_v 0 "NOT_VALID" 1 "VALID" ;
VAL_ 517 e2e_alive_counter 15 "INVALID" ;
VAL_ 517 veh_obj_id3_class 0 "VEH_TYPE_UNKNOWN" 1 "VEH_TYPE_CAR" 2 "VEH_TYPE_TRUCK" 3 "VEH_TYPE_BICYCLE" 4 "VEH_TYPE_MOTORCYCLE" ;
VAL_ 517 veh_obj_id3_detd 0 "ACC_DETN_UNKNOWN" 1 "ACC_DETN_FALSE" 2 "ACC_DETN_TRUE" ;
VAL_ 517 veh_obj_id3_dist_v 0 "NOT_VALID" 1 "VALID" ;
VAL_ 518 e2e_alive_counter 15 "INVALID" ;
VAL_ 518 veh_obj_id4_class 0 "VEH_TYPE_UNKNOWN" 1 "VEH_TYPE_CAR" 2 "VEH_TYPE_TRUCK" 3 "VEH_TYPE_BICYCLE" 4 "VEH_TYPE_MOTORCYCLE" ;
VAL_ 518 veh_obj_id4_detd 0 "ACC_DETN_UNKNOWN" 1 "ACC_DETN_FALSE" 2 "ACC_DETN_TRUE" ;
VAL_ 518 veh_obj_id4_dist_v 0 "NOT_VALID" 1 "VALID" ;
VAL_ 519 e2e_alive_counter 15 "INVALID" ;
VAL_ 519 acc_camera_blk_sts 0 "UNKNOWN" 1 "ACC_VISY_OK" 2 "ACC_VISY_BLKD" ;
VAL_ 519 fvcm_internal_sc 0 "UNKNOWN" 1 "ERR_NOT_PRSNT" 2 "ERR_PRSNT" ;
VAL_ 519 fvcm_pll_oor 0 "UNKNOWN" 1 "ERR_NOT_PRSNT" 2 "ERR_PRSNT" ;
VAL_ 519 fvcm_gpio_err 0 "UNKNOWN" 1 "ERR_NOT_PRSNT" 2 "ERR_PRSNT" ;
VAL_ 519 fvcm_mem_fail 0 "UNKNOWN" 1 "ERR_NOT_PRSNT" 2 "ERR_PRSNT" ;
VAL_ 519 eyeq_boot_err 0 "UNKNOWN" 1 "ERR_NOT_PRSNT" 2 "ERR_PRSNT" ;
VAL_ 519 eyeq_app_msg_timeout 0 "UNKNOWN" 1 "ERR_NOT_PRSNT" 2 "ERR_PRSNT" ;
VAL_ 519 eyeq_uncalibrated 0 "UNKNOWN" 1 "ERR_NOT_PRSNT" 2 "ERR_PRSNT" ;
VAL_ 519 eyeq_out_of_cal 0 "UNKNOWN" 1 "ERR_NOT_PRSNT" 2 "ERR_PRSNT" ;
VAL_ 519 eyeq_out_of_rng 0 "UNKNOWN" 1 "ERR_NOT_PRSNT" 2 "ERR_PRSNT" ;
VAL_ 519 eyeq_out_of_focus 0 "UNKNOWN" 1 "ERR_NOT_PRSNT" 2 "ERR_PRSNT" ;
VAL_ 519 fvcm_bus_off 0 "UNKNOWN" 1 "ERR_NOT_PRSNT" 2 "ERR_PRSNT" ;
VAL_ 519 fvcm_pwr_mod_invalid 0 "UNKNOWN" 1 "ERR_NOT_PRSNT" 2 "ERR_PRSNT" ;
VAL_ 519 acc_camera_blkd_rsn_mask 0 "UNKNOWN" 1 "ACC_BLK_RSN_FOGGY_SPOT" 2 "ACC_BLK_RSN_FRZN_WINDSHIELD" 4 "ACC_BLK_RSN_FULL_BLKD" 8 "ACC_BLK_RSN_PTL_BLKD" 16 "ACC_BLK_RSN_SPLASHES" 32 "ACC_BLK_RSN_LOW_SUN" 64 "ACC_BLK_RSN_BLURRED_IMAGE" 128 "ACC_BLK_RSN_RAIN" 256 "ACC_BLK_RSN_SUN_RAY" 512 "ACC_BLK_RSN_FREE_SIGHT" ;
VAL_ 520 e2e_alive_counter 15 "INVALID" ;
VAL_ 520 lane0_id 0 "ACC_NO_LANE_DETD" ;
VAL_ 520 lane0_location 0 "ACC_LANE_LOCN_LEFT" 1 "ACC_LANE_LOCN_RIGHT" 2 "ACC_LANE_LOCN_NEXT_LEFT" 3 "ACC_LANE_LOCN_NEXT_RIGHT" ;
VAL_ 520 lane0_type 0 "ACC_LANE_TYPE_NO_LINE" 1 "ACC_LANE_TYPE_SOLID" 2 "ACC_LANE_TYPE_DASHED" 3 "ACC_LANE_TYPE_CURBSTONE" 4 "ACC_LANE_TYPE_GRASS" 5 "ACC_LANE_TYPE_BOT_DOTT" 6 "ACC_LANE_TYPE_OTHER" ;
VAL_ 520 lane0_colour 0 "ACC_LANE_COLOUR_NO_LANE" 1 "ACC_LANE_COLOUR_WHITE" 2 "ACC_LANE_COLOUR_RED" 3 "ACC_LANE_COLOUR_YELLOW" 4 "ACC_LANE_COLOUR_OTHER" ;
VAL_ 521 e2e_alive_counter 15 "INVALID" ;
VAL_ 522 e2e_alive_counter 15 "INVALID" ;
VAL_ 522 lane1_id 0 "ACC_NO_LANE_DETD" ;
VAL_ 522 lane1_location 0 "ACC_LANE_LOCN_LEFT" 1 "ACC_LANE_LOCN_RIGHT" 2 "ACC_LANE_LOCN_NEXT_LEFT" 3 "ACC_LANE_LOCN_NEXT_RIGHT" ;
VAL_ 522 lane1_type 0 "ACC_LANE_TYPE_NO_LINE" 1 "ACC_LANE_TYPE_SOLID" 2 "ACC_LANE_TYPE_DASHED" 3 "ACC_LANE_TYPE_CURBSTONE" 4 "ACC_LANE_TYPE_GRASS" 5 "ACC_LANE_TYPE_BOT_DOTT" 6 "ACC_LANE_TYPE_OTHER" ;
VAL_ 522 lane1_colour 0 "ACC_LANE_COLOUR_NO_LANE" 1 "ACC_LANE_COLOUR_WHITE" 2 "ACC_LANE_COLOUR_RED" 3 "ACC_LANE_COLOUR_YELLOW" 4 "ACC_LANE_COLOUR_OTHER" ;
VAL_ 523 e2e_alive_counter 15 "INVALID" ;
VAL_ 524 e2e_alive_counter 15 "INVALID" ;
VAL_ 524 lane2_id 0 "ACC_NO_LANE_DETD" ;
VAL_ 524 lane2_location 0 "ACC_LANE_LOCN_LEFT" 1 "ACC_LANE_LOCN_RIGHT" 2 "ACC_LANE_LOCN_NEXT_LEFT" 3 "ACC_LANE_LOCN_NEXT_RIGHT" ;
VAL_ 524 lane2_type 0 "ACC_LANE_TYPE_NO_LINE" 1 "ACC_LANE_TYPE_SOLID" 2 "ACC_LANE_TYPE_DASHED" 3 "ACC_LANE_TYPE_CURBSTONE" 4 "ACC_LANE_TYPE_GRASS" 5 "ACC_LANE_TYPE_BOT_DOTT" 6 "ACC_LANE_TYPE_OTHER" ;
VAL_ 524 lane2_colour 0 "ACC_LANE_COLOUR_NO_LANE" 1 "ACC_LANE_COLOUR_WHITE" 2 "ACC_LANE_COLOUR_RED" 3 "ACC_LANE_COLOUR_YELLOW" 4 "ACC_LANE_COLOUR_OTHER" ;
VAL_ 525 e2e_alive_counter 15 "INVALID" ;
VAL_ 528 e2e_alive_counter 15 "INVALID" ;
VAL_ 528 lane3_id 0 "ACC_NO_LANE_DETD" ;
VAL_ 528 lane3_location 0 "ACC_LANE_LOCN_LEFT" 1 "ACC_LANE_LOCN_RIGHT" 2 "ACC_LANE_LOCN_NEXT_LEFT" 3 "ACC_LANE_LOCN_NEXT_RIGHT" ;
VAL_ 528 lane3_type 0 "ACC_LANE_TYPE_NO_LINE" 1 "ACC_LANE_TYPE_SOLID" 2 "ACC_LANE_TYPE_DASHED" 3 "ACC_LANE_TYPE_CURBSTONE" 4 "ACC_LANE_TYPE_GRASS" 5 "ACC_LANE_TYPE_BOT_DOTT" 6 "ACC_LANE_TYPE_OTHER" ;
VAL_ 528 lane3_colour 0 "ACC_LANE_COLOUR_NO_LANE" 1 "ACC_LANE_COLOUR_WHITE" 2 "ACC_LANE_COLOUR_RED" 3 "ACC_LANE_COLOUR_YELLOW" 4 "ACC_LANE_COLOUR_OTHER" ;
VAL_ 529 e2e_alive_counter 15 "INVALID" ;
VAL_ 1470 e2e_alive_counter 15 "INVALID" ;
VAL_ 1471 e2e_alive_counter 15 "INVALID" ;
VAL_ 1500 e2e_alive_counter 15 "INVALID" ;
VAL_ 1500 veh_odo_v 0 "NOT_VALID" 1 "VALID" ;
VAL_ 1507 e2e_alive_counter 15 "INVALID" ;
VAL_ 1507 kl30_voltage_v 0 "NOT_VALID" 1 "VALID" ;
VAL_ 1507 kl15_sts 0 "UNKNOWN" 1 "OFF" 2 "ON" 3 "ERROR" ;
VAL_ 1507 kl30_charging 0 "UNKNOWN" 1 "OFF" 2 "ON" ;
VAL_ 1507 kl50_sts 0 "UNKNOWN" 1 "OFF" 2 "ON" ;
VAL_ 1507 klr_sts 0 "UNKNOWN" 1 "OFF" 2 "ON" ;
VAL_ 1510 e2e_alive_counter 15 "INVALID" ;
VAL_ 1510 nm_request 0 "UNKNOWN" 1 "STANDBY_REQUEST" 2 "ACTIVE_REQUEST" 3 "SLEEP_REQUEST" ;
VAL_ 1513 e2e_alive_counter 15 "INVALID" ;
VAL_ 1513 nm_status 0 "UNKNOWN" 1 "STANDBY" 2 "ACTIVE" 3 "READY_SLEEP" 8 "ERR" 9 "STANDBY_ERR" 10 "ACTIVE_ERR" 11 "READY_SLEEP_ERR" ;
VAL_ 1515 e2e_alive_counter 15 "INVALID" ;
VAL_ 1515 nm_status 0 "UNKNOWN" 1 "STANDBY" 2 "ACTIVE" 3 "READY_SLEEP" 8 "ERR" 9 "STANDBY_ERR" 10 "ACTIVE_ERR" 11 "READY_SLEEP_ERR" ;
VAL_ 1518 e2e_alive_counter 15 "INVALID" ;
VAL_ 1821 yaw_rate 65533 "UNAVAILABLE" 65534 "INVALID" 65535 "UNFILLED" ;
VAL_ 1821 yaw_rate_qual 0 "UNKNOWN" 15 "INVALID" ;
VAL_ 1821 lat_acc_qual 0 "UNKNOWN" 2 "VALID" 4 "SUBSTITUTE" 6 "INVALID" 14 "UNAVAILABLE" 15 "UNFILLED" ;
VAL_ 1821 lat_acc 65533 "UNAVAILABLE" 65534 "INVALID" 65535 "UNFILLED" ;
VAL_ 1821 sc_sts 0 "NO_MISTAKE" 2 "UNDERVOLTAGE" 3 "OVERVOLTAGE" 4 "SYNC_UNDERFLOW" 5 "SYNC_FAIL" 13 "FUNC_NOT_AVAILABLE" 14 "FUNC_ERROR" 15 "UNFILLED" ;
VAL_ 1822 roll_rate 65533 "UNAVAILABLE" 65534 "INVALID" 65535 "UNFILLED" ;
VAL_ 1822 roll_rate_qual 0 "UNKNOWN" 2 "VALID" 4 "SUBSTITUTE" 6 "INVALID" 14 "UNAVAILABLE" 15 "UNFILLED" ;
VAL_ 1822 long_acc_qual 0 "UNKNOWN" 2 "VALID" 4 "SUBSTITUTE" 6 "INVALID" 14 "UNAVAILABLE" 15 "UNFILLED" ;
VAL_ 1822 long_acc 65533 "UNAVAILABLE" 65534 "INVALID" 65535 "UNFILLED" ;
VAL_ 1823 pitch_rate 65533 "UNAVAILABLE" 65534 "INVALID" 65535 "UNFILLED" ;
VAL_ 1823 pitch_rate_qual 2 "VALID" 4 "SUBSTITUTE" 6 "INVALID" 14 "UNAVAILABLE" 15 "UNFILLED" ;
VAL_ 1823 vert_acc_qual 0 "UNKNOWN" 2 "VALID" 4 "SUBSTITUTE" 6 "INVALID" 14 "UNAVAILABLE" 15 "UNFILLED" ;
VAL_ 1823 vert_acc 65533 "UNAVAILABLE" 65534 "INVALID" 65535 "UNFILLED" ;
VAL_ 1890 diag_request 0 "CUSTOMER_NUM" 1 "MANUFACTURER_NUM" 2 "SERIAL_NUM_P1" 3 "SERIAL_NUM_P2" 4 "SW_RELEASE_NUM" 5 "HW_RELEASE_NUM" 15 "UNFILLED" ;
VAL_ 1890 reset_request 0 "OFF" 1 "ON" 13 "UNAVAILABLE" 14 "FAILURE" 15 "UNFILLED" ;
VAL_ 2003 dtc_severity_level 0 "NOT_USED" 1 "LEVEL1" 2 "LEVEL2" 3 "LEVEL3" 4 "LEVEL4" ;
VAL_ 2003 dtc_type 0 "NOT_USED" 1 "TYPE_A" 2 "TYPE_B" 3 "TYPE_C" 4 "TYPE_D" 5 "TYPE_E" 6 "TYPE_F" ;
